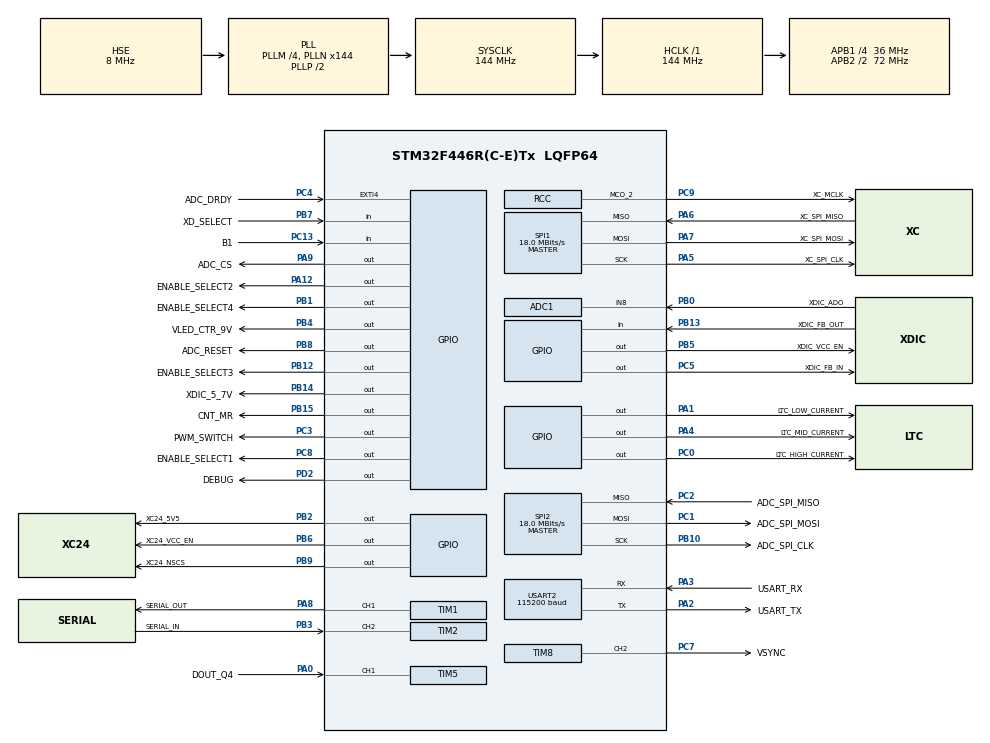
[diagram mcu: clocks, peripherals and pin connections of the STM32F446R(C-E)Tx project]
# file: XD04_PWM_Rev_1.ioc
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ADC1.Channel-0\#ChannelRegularConversion=ADC_CHANNEL_8
ADC1.ContinuousConvMode=DISABLE
ADC1.NbrOfConversionFlag=1
ADC1.Rank-0\#ChannelRegularConversion=1
ADC1.SamplingTime-0\#ChannelRegularConversion=ADC_SAMPLETIME_480CYCLES
ADC1.ScanConvMode=DISABLE
ADC1.master=1
Dma.Request0=TIM1_CH1
Dma.Request1=TIM5_CH1
Dma.Request2=TIM2_CH2/CH4
Dma.TIM1_CH1.0.Direction=DMA_MEMORY_TO_PERIPH
Dma.TIM1_CH1.0.FIFOMode=DMA_FIFOMODE_DISABLE
Dma.TIM1_CH1.0.Instance=DMA2_Stream1
Dma.TIM1_CH1.0.MemDataAlignment=DMA_MDATAALIGN_HALFWORD
Dma.TIM1_CH1.0.MemInc=DMA_MINC_ENABLE
Dma.TIM1_CH1.0.Mode=DMA_NORMAL
Dma.TIM1_CH1.0.PeriphDataAlignment=DMA_PDATAALIGN_HALFWORD
Dma.TIM1_CH1.0.PeriphInc=DMA_PINC_DISABLE
Dma.TIM1_CH1.0.Priority=DMA_PRIORITY_LOW
Dma.TIM2_CH2/CH4.2.Direction=DMA_PERIPH_TO_MEMORY
Dma.TIM2_CH2/CH4.2.FIFOMode=DMA_FIFOMODE_DISABLE
Dma.TIM2_CH2/CH4.2.Instance=DMA1_Stream6
Dma.TIM2_CH2/CH4.2.MemDataAlignment=DMA_MDATAALIGN_HALFWORD
Dma.TIM2_CH2/CH4.2.MemInc=DMA_MINC_ENABLE
Dma.TIM2_CH2/CH4.2.Mode=DMA_NORMAL
Dma.TIM2_CH2/CH4.2.PeriphDataAlignment=DMA_PDATAALIGN_HALFWORD
Dma.TIM2_CH2/CH4.2.PeriphInc=DMA_PINC_DISABLE
Dma.TIM2_CH2/CH4.2.Priority=DMA_PRIORITY_LOW
Dma.TIM5_CH1.1.Direction=DMA_PERIPH_TO_MEMORY
Dma.TIM5_CH1.1.FIFOMode=DMA_FIFOMODE_DISABLE
Dma.TIM5_CH1.1.Instance=DMA1_Stream2
Dma.TIM5_CH1.1.MemDataAlignment=DMA_MDATAALIGN_WORD
Dma.TIM5_CH1.1.MemInc=DMA_MINC_ENABLE
Dma.TIM5_CH1.1.Mode=DMA_NORMAL
Dma.TIM5_CH1.1.PeriphDataAlignment=DMA_PDATAALIGN_WORD
Dma.TIM5_CH1.1.PeriphInc=DMA_PINC_DISABLE
Dma.TIM5_CH1.1.Priority=DMA_PRIORITY_LOW
Mcu.Family=STM32F4
Mcu.Name=STM32F446R(C-E)Tx
Mcu.Package=LQFP64
NVIC.DMA1_Stream2_IRQn=true\:0\:0\:false\:false\:true\:false\:true\:true
NVIC.DMA1_Stream6_IRQn=true\:0\:0\:false\:false\:true\:false\:true\:true
NVIC.DMA2_Stream1_IRQn=true\:0\:0\:false\:false\:true\:false\:true\:true
NVIC.EXTI4_IRQn=true\:0\:0\:false\:false\:true\:true\:true\:true
NVIC.PriorityGroup=NVIC_PRIORITYGROUP_4
NVIC.TIM8_UP_TIM13_IRQn=true\:1\:0\:true\:false\:true\:true\:true\:true
NVIC.USART2_IRQn=true\:5\:0\:true\:false\:true\:true\:true\:true
PA0-WKUP.GPIO_Label=DOUT_Q4
PA0-WKUP.GPIO_PuPd=GPIO_NOPULL
PA0-WKUP.Signal=S_TIM5_CH1
PA1.GPIO_Label=LTC_LOW_CURRENT
PA1.GPIO_Speed=GPIO_SPEED_FREQ_VERY_HIGH
PA1.PinState=GPIO_PIN_SET
PA1.Signal=GPIO_Output
PA12.GPIO_Label=ENABLE_SELECT2
PA12.GPIO_Speed=GPIO_SPEED_FREQ_VERY_HIGH
PA12.PinState=GPIO_PIN_SET
PA12.Signal=GPIO_Output
PA13.GPIO_Label=TMS
PA13.Mode=Serial_Wire
PA13.Signal=SYS_JTMS-SWDIO
PA14.GPIO_Label=TCK
PA14.Mode=Serial_Wire
PA14.Signal=SYS_JTCK-SWCLK
PA2.GPIO_Label=USART_TX
PA2.Mode=Asynchronous
PA2.Signal=USART2_TX
PA3.GPIO_Label=USART_RX
PA3.Mode=Asynchronous
PA3.Signal=USART2_RX
PA4.GPIO_Label=LTC_MID_CURRENT
PA4.GPIO_Speed=GPIO_SPEED_FREQ_VERY_HIGH
PA4.PinState=GPIO_PIN_SET
PA4.Signal=GPIO_Output
PA5.GPIO_Label=XC_SPI_CLK
PA5.Mode=Full_Duplex_Master
PA5.Signal=SPI1_SCK
PA6.GPIO_Label=XC_SPI_MISO
PA6.Mode=Full_Duplex_Master
PA6.Signal=SPI1_MISO
PA7.GPIO_Label=XC_SPI_MOSI
PA7.Mode=Full_Duplex_Master
PA7.Signal=SPI1_MOSI
PA8.GPIO_Label=SERIAL_OUT
PA8.GPIO_PuPd=GPIO_PULLDOWN
PA8.GPIO_Speed=GPIO_SPEED_FREQ_VERY_HIGH
PA8.Signal=S_TIM1_CH1
PA9.GPIO_Label=ADC_CS
PA9.GPIO_Speed=GPIO_SPEED_FREQ_VERY_HIGH
PA9.PinState=GPIO_PIN_SET
PA9.Signal=GPIO_Output
PB0.GPIO_Label=XDIC_ADO
PB0.Signal=ADCx_IN8
PB1.GPIO_Label=ENABLE_SELECT4
PB1.GPIO_Speed=GPIO_SPEED_FREQ_VERY_HIGH
PB1.PinState=GPIO_PIN_SET
PB1.Signal=GPIO_Output
PB10.GPIO_Label=ADC_SPI_CLK
PB10.Mode=Full_Duplex_Master
PB10.Signal=SPI2_SCK
PB12.GPIO_Label=ENABLE_SELECT3
PB12.GPIO_Speed=GPIO_SPEED_FREQ_VERY_HIGH
PB12.PinState=GPIO_PIN_SET
PB12.Signal=GPIO_Output
PB13.GPIO_Label=XDIC_FB_OUT
PB13.Signal=GPIO_Input
PB14.GPIO_Label=XDIC_5_7V
PB14.GPIO_Speed=GPIO_SPEED_FREQ_VERY_HIGH
PB14.Signal=GPIO_Output
PB15.GPIO_Label=CNT_MR
PB15.PinState=GPIO_PIN_SET
PB15.Signal=GPIO_Output
PB2.GPIO_Label=XC24_5V5
PB2.Signal=GPIO_Output
PB3.GPIO_Label=SERIAL_IN
PB3.GPIO_PuPd=GPIO_PULLDOWN
PB3.GPIO_Speed=GPIO_SPEED_FREQ_VERY_HIGH
PB3.Signal=S_TIM2_CH2
PB4.GPIO_Label=VLED_CTR_9V
PB4.GPIO_Speed=GPIO_SPEED_FREQ_VERY_HIGH
PB4.PinState=GPIO_PIN_SET
PB4.Signal=GPIO_Output
PB5.GPIO_Label=XDIC_VCC_EN
PB5.GPIO_Speed=GPIO_SPEED_FREQ_VERY_HIGH
PB5.PinState=GPIO_PIN_SET
PB5.Signal=GPIO_Output
PB6.GPIO_Label=XC24_VCC_EN
PB6.Signal=GPIO_Output
PB7.GPIO_Label=XD_SELECT
PB7.Signal=GPIO_Input
PB8.GPIO_Label=ADC_RESET
PB8.PinState=GPIO_PIN_SET
PB8.Signal=GPIO_Output
PB9.GPIO_Label=XC24_NSCS
PB9.GPIO_Speed=GPIO_SPEED_FREQ_VERY_HIGH
PB9.Signal=GPIO_Output
PC0.GPIO_Label=LTC_HIGH_CURRENT
PC0.GPIO_Speed=GPIO_SPEED_FREQ_VERY_HIGH
PC0.PinState=GPIO_PIN_SET
PC0.Signal=GPIO_Output
PC1.GPIO_Label=ADC_SPI_MOSI
PC1.Mode=Full_Duplex_Master
PC1.Signal=SPI2_MOSI
PC13.GPIO_Label=B1
PC13.GPIO_PuPd=GPIO_PULLUP
PC13.Signal=GPIO_Input
PC14-OSC32_IN.Mode=LSE-External-Oscillator
PC14-OSC32_IN.Signal=RCC_OSC32_IN
PC15-OSC32_OUT.Mode=LSE-External-Oscillator
PC15-OSC32_OUT.Signal=RCC_OSC32_OUT
PC2.GPIO_Label=ADC_SPI_MISO
PC2.Mode=Full_Duplex_Master
PC2.Signal=SPI2_MISO
PC3.GPIO_Label=PWM_SWITCH
PC3.GPIO_Speed=GPIO_SPEED_FREQ_VERY_HIGH
PC3.Signal=GPIO_Output
PC4.GPIO_Label=ADC_DRDY
PC4.GPIO_ModeDefaultEXTI=GPIO_MODE_IT_FALLING
PC4.GPIO_PuPd=GPIO_PULLUP
PC4.Signal=GPXTI4
PC5.GPIO_Label=XDIC_FB_IN
PC5.Signal=GPIO_Output
PC7.GPIO_Label=VSYNC
PC7.Signal=S_TIM8_CH2
PC8.GPIO_Label=ENABLE_SELECT1
PC8.GPIO_Speed=GPIO_SPEED_FREQ_VERY_HIGH
PC8.PinState=GPIO_PIN_SET
PC8.Signal=GPIO_Output
PC9.GPIO_Label=XC_MCLK
PC9.Mode=Clock-out-2
PC9.Signal=RCC_MCO_2
PD2.GPIO_Label=DEBUG
PD2.Signal=GPIO_Output
PH0-OSC_IN.Mode=HSE-External-Oscillator
PH0-OSC_IN.Signal=RCC_OSC_IN
PH1-OSC_OUT.Mode=HSE-External-Oscillator
PH1-OSC_OUT.Signal=RCC_OSC_OUT
ProjectManager.HeapSize=0x200
ProjectManager.StackSize=0x800
ProjectManager.TargetToolchain=EWARM V8.32
RCC.48MHZClocksFreq_Value=84000000
RCC.AHBFreq_Value=144000000
RCC.APB1CLKDivider=RCC_HCLK_DIV4
RCC.APB1Freq_Value=36000000
RCC.APB1TimFreq_Value=72000000
RCC.APB2CLKDivider=RCC_HCLK_DIV2
RCC.APB2Freq_Value=72000000
RCC.APB2TimFreq_Value=144000000
RCC.CortexFreq_Value=144000000
RCC.FLatency-AdvancedSettings=FLASH_LATENCY_4
RCC.HCLKFreq_Value=144000000
RCC.HSE_VALUE=8000000
RCC.HSI_VALUE=16000000
RCC.PLLI2SM=8
RCC.PLLI2SN=400
RCC.PLLI2SR=4
RCC.PLLM=4
RCC.PLLN=144
RCC.PLLSourceVirtual=RCC_PLLSOURCE_HSE
RCC.RCC_MCO1Source=RCC_MCO1SOURCE_PLLCLK
RCC.RCC_MCO2Source=RCC_MCO2SOURCE_PLLI2SCLK
RCC.RCC_MCODiv2=RCC_MCODIV_4
RCC.SYSCLKFreq_VALUE=144000000
RCC.SYSCLKSource=RCC_SYSCLKSOURCE_PLLCLK
RCC.USBFreq_Value=144000000
RCC.VCOOutputFreq_Value=288000000
SH.ADCx_IN8.0=ADC1_IN8,IN8
SH.S_TIM1_CH1.0=TIM1_CH1,PWM Generation1 CH1
SH.S_TIM2_CH2.0=TIM2_CH2,PWM_Input_2
SH.S_TIM5_CH1.0=TIM5_CH1,Input_Capture1_from_TI1
SH.S_TIM8_CH2.0=TIM8_CH2,PWM Generation2 CH2
SPI1.BaudRatePrescaler=SPI_BAUDRATEPRESCALER_4
SPI1.CLKPhase=SPI_PHASE_2EDGE
SPI1.CalculateBaudRate=18.0 MBits/s
SPI1.DataSize=SPI_DATASIZE_16BIT
SPI1.Direction=SPI_DIRECTION_2LINES
SPI1.Mode=SPI_MODE_MASTER
SPI1.VirtualType=VM_MASTER
SPI2.BaudRatePrescaler=SPI_BAUDRATEPRESCALER_2
SPI2.CLKPhase=SPI_PHASE_2EDGE
SPI2.CalculateBaudRate=18.0 MBits/s
SPI2.Direction=SPI_DIRECTION_2LINES
SPI2.Mode=SPI_MODE_MASTER
SPI2.VirtualType=VM_MASTER
TIM1.AutomaticOutput=TIM_AUTOMATICOUTPUT_ENABLE
TIM1.Channel-PWM\ Generation1\ CH1=TIM_CHANNEL_1
TIM1.Period=143
TIM12.AutoReloadPreload=TIM_AUTORELOAD_PRELOAD_ENABLE
TIM12.ClockDivision=TIM_CLOCKDIVISION_DIV1
TIM12.Period=65535
TIM12.Prescaler=71
TIM2.ICPolarity_1=TIM_INPUTCHANNELPOLARITY_FALLING
TIM5.AutoReloadPreload=TIM_AUTORELOAD_PRELOAD_ENABLE
TIM5.Channel-Input_Capture1_from_TI1=TIM_CHANNEL_1
TIM5.Prescaler=0
TIM8.AutomaticOutput=TIM_AUTOMATICOUTPUT_ENABLE
TIM8.Channel-PWM\ Generation2\ CH2=TIM_CHANNEL_2
TIM8.Period=39999
TIM8.Prescaler=29
TIM8.Pulse-PWM\ Generation2\ CH2=40
USART2.BaudRate=115200
USART2.VirtualMode=VM_ASYNC
VP_TIM12_VS_ClockSourceINT.Mode=Internal
VP_TIM1_VS_ClockSourceINT.Mode=Internal
VP_TIM2_VS_ClockSourceINT.Mode=Internal
VP_TIM5_VS_ClockSourceINT.Mode=Internal
VP_TIM8_VS_ClockSourceINT.Mode=Internal
board=NUCLEO-F446RE

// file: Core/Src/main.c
/* USER CODE BEGIN Header */
/**
  ******************************************************************************
  * @file           : main.c
  * @brief          : Main program body
  ******************************************************************************
  * @attention
  *
  * <h2><center>&copy; Copyright (c) 2021 STMicroelectronics.
  * All rights reserved.</center></h2>
  *
  * This software component is licensed by ST under Ultimate Liberty license
  * SLA0044, the "License"; You may not use this file except in compliance with
  * the License. You may obtain a copy of the License at:
  *                             www.st.com/SLA0044
  *
  ******************************************************************************
  */
#define __XDIC_MAIN_C__
#include <stdint.h>
/* USER CODE END Header */
#include "main.h"

/* USER CODE BEGIN Includes */
#include "config.h"
#include "types.h"
#include "jigbd_if.h"
#include "xc24.h"
#include "xd_trim.h"
#include "ads124s08.h"
#include "vsync_task.h"
#include "xdic.h"
#include "xc_trim.h"
/* USER CODE END Includes */

/* USER CODE BEGIN PD */
#define RX_PACKET_SIZE  64
#define RX_BUFF_SIZE    32

typedef void (*func_t)(void);

typedef struct tag_KEY_INFO
{
    uint32_t now_state;
    uint32_t prev_state;
    uint8_t press_cnt;
    uint8_t odd_even;
    func_t function[2];
} key_info_t;
/* USER CODE END PD */

/* USER CODE BEGIN PV */
void key_func_1(void)
{
    XDIC_Sweep_LDO();
}

void key_func_2(void)
{
    // Off LED
    NVIC_SystemReset();
}

static key_info_t gt_key_info = {
    .now_state = 1,
    .prev_state = 1,
    .press_cnt = 0,
    .odd_even = 0,
    .function = { key_func_1, key_func_2 },
};

static uint8_t gn_key_task_tick;

void btn_process(void)
{
    if (gn_key_task_tick == 0)
    {
        gt_key_info.now_state = LL_GPIO_IsInputPinSet(B1_GPIO_Port, B1_Pin);
        if (gt_key_info.now_state != gt_key_info.prev_state)
        {
            if (gt_key_info.now_state == 0)
            {
            }
            else
            {
                // Button Released
                if (gt_key_info.press_cnt >= 30)
                {
                    if (gt_key_info.function[gt_key_info.odd_even] != NULL)
                    {
                        gt_key_info.function[gt_key_info.odd_even]();
                    }
                    gt_key_info.odd_even ^= 1;
                }
                gt_key_info.press_cnt = 0;
            }
            gt_key_info.prev_state = gt_key_info.now_state;
        }
        else
        {
            if (gt_key_info.now_state == 0)
            {
                // Button Pressed
                ++gt_key_info.press_cnt;
            }
            else
            {
                // nothing
            }
        }
        gn_key_task_tick = 10; //10ms
    }
}

typedef struct
{
    uint16_t length;
    char buffer[RX_PACKET_SIZE];
} rx_packet_t;

typedef struct
{
    uint16_t RxInCnt;
    uint16_t RxOutCnt;
    rx_packet_t Rxbuff[RX_BUFF_SIZE];
} RX_UART_t;
static RX_UART_t gt_rx_uart;

static bool gb_xd_run_trim_task;
static bool gb_xd_run_screen_task;

static bool gb_xc_run_trim_task;

static LOG_LV_T gt_log_lv = LOG_INFO;
/* USER CODE END PV */

void SystemClock_Config(void);
void PeriphCommonClock_Config(void);
static void MX_GPIO_Init(void);
static void MX_DMA_Init(void);
static void MX_USART2_UART_Init(void);
static void MX_TIM12_Init(void);
static void MX_SPI2_Init(void);
static void MX_TIM5_Init(void);
static void MX_SPI1_Init(void);
static void MX_ADC1_Init(void);
static void MX_TIM8_Init(void);
static void MX_TIM1_Init(void);
static void MX_TIM2_Init(void);
/* USER CODE BEGIN PFP */
static void JigTestMainTask(void);
static void TaskDebugUart(void);
/* USER CODE END PFP */

/* USER CODE BEGIN 0 */
void sys_tick_handler(void)
{
    if (gb_xd_run_trim_task == false)
    {
        gb_xd_run_trim_task = true;
    }
    if (gb_xd_run_screen_task == false)
    {
        gb_xd_run_screen_task = true;
    }
    if (gb_xc_run_trim_task == false)
    {
        gb_xc_run_trim_task = true;
    }
    if (gn_xd_rx_timeout)
    {
        --gn_xd_rx_timeout;
    }
    if (gn_xc_spi_timeout)
    {
        --gn_xc_spi_timeout;
    }
    if (gn_key_task_tick)
    {
        --gn_key_task_tick;
    }
    if (gn_ads114s08_read_timeout)
    {
        --gn_ads114s08_read_timeout;
    }
}

void print(LOG_LV_T log_lv, const char *fmt, ...)
{
    if (log_lv >= gt_log_lv)
    {
        int len = 0;
        char msg_buffer[PRINT_BUFF_SIZE] = {0, };

        if (log_lv > LOG_INFO)
        {
            char temp_buffer[PRINT_BUFF_SIZE] = {0, };
            snprintf(temp_buffer, PRINT_BUFF_SIZE - 1, "%s%s%s", ANSI_FONT_RED, fmt, ANSI_FONT_NONE);
            fmt = temp_buffer;
        }

        va_list ap;
        va_start(ap, fmt);
        len = vsnprintf(msg_buffer, (PRINT_BUFF_SIZE - 1), fmt, ap);
        va_end(ap);

        for (int i = 0 ; i < len ; ++i)
        {
            /* Loop until the end of transmission */
            while (RESET == LL_USART_IsActiveFlag_TXE(USART2));
            /* Echo received character on TX */
            LL_USART_TransmitData8(USART2, (uint8_t)msg_buffer[i]);
        }
    }
}

void comm_print_help(void)
{
    print(LOG_INFO, "\n\r------------------ Command Help -----------------------------");

    print(LOG_INFO, "\n\r  help / ?\t\t : Show command help");
    print(LOG_INFO, "\n\r  jig_ic_start\t\t : Start timer for frequency input capture");
    print(LOG_INFO, "\n\r  jig_ic_stop\t\t : Stop input capture and print measured frequency");
    print(LOG_INFO, "\n\r  jig_vref_start\t : Start MCU ADC");

    print(LOG_INFO, "\n\r  jig_ch_sel [d]\t : Select output channel (0 ~ XD_CH_MAX)");
    print(LOG_INFO, "\n\r  jig_xd_vcc [u]\t : XD VCC On/Off (1=On, 0=Off)");
    print(LOG_INFO, "\n\r  jig_xd_vcc_level [u]\t : XD VCC level (0=5V, 1=5.7V)");
    print(LOG_INFO, "\n\r  jig_xc_vcc [u]\t : XC VCC On/Off (1=On, 0=Off)");
    print(LOG_INFO, "\n\r  jig_vled [u]\t\t : VLED 9V On/Off (1=On, 0=Off)");
    print(LOG_INFO, "\n\r  jig_gain [u]\t\t : Set current gain (0 ~ GAIN_MAX-1)");
    print(LOG_INFO, "\n\r  jig_vsync [d]\t\t : Start/Stop Vsync (1=Start, 0=Stop)");
    print(LOG_INFO, "\n\r  vsync [lf]\t\t : Set vsync frequency (Hz)");
    print(LOG_INFO, "\n\r  pwm_freq [lf]\t\t : Set PWM frequency (kHz)");

    print(LOG_INFO, "\n\r  xd_idgen\t\t : Send IDGEN command to XDIC");
    print(LOG_INFO, "\n\r  xd_reset\t\t : Reset XDIC");
    print(LOG_INFO, "\n\r  xd_syncgen\t\t : Send SYNCGEN command to XDIC");
    print(LOG_INFO, "\n\r  xd_test_en\t\t : Enter trim mode of XDIC");
    print(LOG_INFO, "\n\r  xd_r_all\t\t : Read all registers of XDIC");
    print(LOG_INFO, "\n\r  xd_r [x]\t\t : Read general register [x] (HEX)");
    print(LOG_INFO, "\n\r  xd_rt [x]\t\t : Read trim register [x] (HEX)");
    print(LOG_INFO, "\n\r  xd_w [x] [y]\t\t : Write [y] to general register [x] (HEX)");
    print(LOG_INFO, "\n\r  xd_wt [x] [y]\t\t : Write [y] to trim register [x] (HEX)");
    print(LOG_INFO, "\n\r  xd_ldim [d]\t\t : Set LDIM value [0 ~ 65535]");
    print(LOG_INFO, "\n\r  xd_ldim\t\t : Show current LDIM value");
    print(LOG_INFO, "\n\r  xd_fbi [x]\t\t : Set FBI pin (1=HI, 0=LO)");
    print(LOG_INFO, "\n\r  xd_fbo\t\t : Read FBO pin status");
    print(LOG_INFO, "\n\r  xd_ch [d]\t\t : Set XDIC channel (0 ~ XD_CH_MAX)");

    print(LOG_INFO, "\n\r  xd_debug\t\t : Initialize XD debug environment");
    print(LOG_INFO, "\n\r  xd_trim_debug\t : Initialize XD trim environment");
    print(LOG_INFO, "\n\r  xd_trim_vref\t\t : Trim VREF of XDIC");
    print(LOG_INFO, "\n\r  xd_trim_osc\t\t : Trim OSC of XDIC");
    print(LOG_INFO, "\n\r  xd_trim_ofs [x]\t : Trim offset and fix LD to 1<<12");
    print(LOG_INFO, "\n\r  xd_trim_gain [x]\t : Trim gain and fix LD to 6<<12");
    print(LOG_INFO, "\n\r  xd_osc_debug\t\t : Auto scan OSC trim values");

    print(LOG_INFO, "\n\r  xc_debug\t\t : Initialize XC24");
    print(LOG_INFO, "\n\r  xc_r [x]\t\t : Read register [x] of XC24 (HEX)");
    print(LOG_INFO, "\n\r  xc_w [x] [y]\t\t : Write [y] to register [x] of XC24 (HEX)");
    print(LOG_INFO, "\n\r  xc_r_all\t\t : Read all registers of XC24");
    print(LOG_INFO, "\n\r  xc_use [d]\t\t : Enable/Disable XC24 usage (0/1)");

    print(LOG_INFO, "\n\r  xd_trim_start / 1\t : Start XDIC trim process");
    print(LOG_INFO, "\n\r  xd_screen_start / 2\t : Start XDIC screen process");
    print(LOG_INFO, "\n\r  xd_dimming_start / 3\t : Start XDIC dimming process");
    print(LOG_INFO, "\n\r  xc_trim_start / 4\t : Start XC24 trim process");

    print(LOG_INFO, "\n\r  log_lv [d]\t\t : Set log level (0 ~ LOG_MAX-1)");
    print(LOG_INFO, "\n\r  reset\t\t\t : Reset MCU");

    print(LOG_INFO, "\n\r--------------------------------------------------------------\n\r");
}

void comm_init(void)
{
    print(LOG_INFO, "\n\r--------------------------------------");
    print(LOG_INFO, "\n\r    [GT-XD04 PWM (ES2) JIG]");
    print(LOG_INFO, "\n\r--------------------------------------");
    print(LOG_INFO, "\n\r - Author: xxx@glbltech.com");
    print(LOG_INFO, "\n\r - Build : %s", __DATE__);
    print(LOG_INFO, "\r\n -%s %s %s", ANSI_FONT_YELLOW, (IS_XC24_Support() ? "XC24 ES2 REV ES2 IS SELECTED!" : "NOT SUPPORT XC24"), ANSI_FONT_NONE);
    print(LOG_INFO, "\r\n -%s %s %s", ANSI_FONT_YELLOW, (XD_Trim_IF_Get_OTP_Enable() ? "XDIC OTP WRITE ENABLE" : "XDIC OTP WRITE DISABLE"), ANSI_FONT_NONE);
    print(LOG_INFO, "\r\n -%s %s %s", ANSI_FONT_YELLOW, (XC_Trim_IF_Get_OTP_Enable() ? "XC24 OTP WRITE ENABLE" : "XC24 OTP WRITE DISABLE"), ANSI_FONT_NONE);
    print(LOG_INFO, "\n\r--------------------------------------\r\n");
}
/* USER CODE END 0 */

int main(void)
{

  /* MCU Configuration--------------------------------------------------------*/

  /* Reset of all peripherals, Initializes the Flash interface and the Systick. */
  HAL_Init();

  /* Configure the system clock */
  SystemClock_Config();

  /* Configure the peripherals common clocks */
  PeriphCommonClock_Config();

  /* Initialize all configured peripherals */
  MX_GPIO_Init();
  MX_DMA_Init();
  MX_USART2_UART_Init();
  MX_TIM12_Init();
  MX_SPI2_Init();
  MX_TIM5_Init();
  MX_SPI1_Init();
  MX_ADC1_Init();
  MX_TIM8_Init();
  MX_TIM1_Init();
  MX_TIM2_Init();
  /* USER CODE BEGIN 2 */

    USE_XC24(FALSE);
    XD_Trim_IF_Set_OTP_Enable(FALSE);
    XC_Trim_IF_Set_OTP_Enable(FALSE);
    XC24_Start_MCLK_Oscillation(FALSE);
    JigBD_IF_Link_DMA_With_Buffer();

    XD_Trim_Calculate_Spec();
    ADS114S08_Init();

    LL_TIM_EnableCounter(TIM1); /* PWM Output for ... */
    LL_TIM_EnableCounter(TIM2); /* PWM Input for ... */
    LL_TIM_EnableCounter(TIM5); /* for Freq Input */

    /* DMA2_Stream2_IRQn interrupt configuration */
    NVIC_SetPriority(DMA2_Stream2_IRQn, NVIC_EncodePriority(NVIC_GetPriorityGrouping(),0, 0));
    NVIC_EnableIRQ(DMA2_Stream2_IRQn);

    comm_init();

  /* USER CODE END 2 */

  /* Infinite loop */
  while (1)
  {

    /* USER CODE BEGIN 3 */
    JigTestMainTask();
    TaskDebugUart();
    XDIC_Vsync_Task();
    btn_process();
  }
  /* USER CODE END 3 */
}

void SystemClock_Config(void)
{
  RCC_OscInitTypeDef RCC_OscInitStruct = {0};
  RCC_ClkInitTypeDef RCC_ClkInitStruct = {0};

  /** Configure the main internal regulator output voltage
  */
  __HAL_RCC_PWR_CLK_ENABLE();
  __HAL_PWR_VOLTAGESCALING_CONFIG(PWR_REGULATOR_VOLTAGE_SCALE1);

  /** Initializes the RCC Oscillators according to the specified parameters
  * in the RCC_OscInitTypeDef structure.
  */
  RCC_OscInitStruct.OscillatorType = RCC_OSCILLATORTYPE_HSE;
  RCC_OscInitStruct.HSEState = RCC_HSE_ON;
  RCC_OscInitStruct.HSIState = RCC_HSI_ON;
  RCC_OscInitStruct.HSICalibrationValue = RCC_HSICALIBRATION_DEFAULT;
  RCC_OscInitStruct.PLL.PLLState = RCC_PLL_ON;
  RCC_OscInitStruct.PLL.PLLSource = RCC_PLLSOURCE_HSE;
  RCC_OscInitStruct.PLL.PLLM = 4;
  RCC_OscInitStruct.PLL.PLLN = 144;
  RCC_OscInitStruct.PLL.PLLP = RCC_PLLP_DIV2;
  RCC_OscInitStruct.PLL.PLLQ = 2;
  RCC_OscInitStruct.PLL.PLLR = 2;
  if (HAL_RCC_OscConfig(&RCC_OscInitStruct) != HAL_OK)
  {
    Error_Handler();
  }

  /** Initializes the CPU, AHB and APB buses clocks
  */
  RCC_ClkInitStruct.ClockType = RCC_CLOCKTYPE_HCLK|RCC_CLOCKTYPE_SYSCLK
                              |RCC_CLOCKTYPE_PCLK1|RCC_CLOCKTYPE_PCLK2;
  RCC_ClkInitStruct.SYSCLKSource = RCC_SYSCLKSOURCE_PLLCLK;
  RCC_ClkInitStruct.AHBCLKDivider = RCC_SYSCLK_DIV1;
  RCC_ClkInitStruct.APB1CLKDivider = RCC_HCLK_DIV4;
  RCC_ClkInitStruct.APB2CLKDivider = RCC_HCLK_DIV2;

  if (HAL_RCC_ClockConfig(&RCC_ClkInitStruct, FLASH_LATENCY_4) != HAL_OK)
  {
    Error_Handler();
  }
  HAL_RCC_MCOConfig(RCC_MCO2, RCC_MCO2SOURCE_PLLI2SCLK, RCC_MCODIV_4);
}

void PeriphCommonClock_Config(void)
{
  RCC_PeriphCLKInitTypeDef PeriphClkInitStruct = {0};

  /** Initializes the peripherals clock
  */
  PeriphClkInitStruct.PeriphClockSelection = RCC_PERIPHCLK_PLLI2S;
  PeriphClkInitStruct.PLLI2S.PLLI2SN = 400;
  PeriphClkInitStruct.PLLI2S.PLLI2SP = RCC_PLLI2SP_DIV2;
  PeriphClkInitStruct.PLLI2S.PLLI2SM = 8;
  PeriphClkInitStruct.PLLI2S.PLLI2SR = 4;
  PeriphClkInitStruct.PLLI2S.PLLI2SQ = 2;
  PeriphClkInitStruct.PLLI2SDivQ = 1;
  if (HAL_RCCEx_PeriphCLKConfig(&PeriphClkInitStruct) != HAL_OK)
  {
    Error_Handler();
  }
}

static void MX_ADC1_Init(void)
{

  LL_ADC_InitTypeDef ADC_InitStruct = {0};
  LL_ADC_REG_InitTypeDef ADC_REG_InitStruct = {0};
  LL_ADC_CommonInitTypeDef ADC_CommonInitStruct = {0};

  LL_GPIO_InitTypeDef GPIO_InitStruct = {0};

  /* Peripheral clock enable */
  LL_APB2_GRP1_EnableClock(LL_APB2_GRP1_PERIPH_ADC1);

  LL_AHB1_GRP1_EnableClock(LL_AHB1_GRP1_PERIPH_GPIOB);
  /**ADC1 GPIO Configuration
  PB0   ------> ADC1_IN8
  */
  GPIO_InitStruct.Pin = XDIC_ADO_Pin;
  GPIO_InitStruct.Mode = LL_GPIO_MODE_ANALOG;
  GPIO_InitStruct.Pull = LL_GPIO_PULL_NO;
  LL_GPIO_Init(XDIC_ADO_GPIO_Port, &GPIO_InitStruct);

  /** Common config
  */
  ADC_InitStruct.Resolution = LL_ADC_RESOLUTION_12B;
  ADC_InitStruct.DataAlignment = LL_ADC_DATA_ALIGN_RIGHT;
  ADC_InitStruct.SequencersScanMode = LL_ADC_SEQ_SCAN_DISABLE;
  LL_ADC_Init(ADC1, &ADC_InitStruct);
  ADC_REG_InitStruct.TriggerSource = LL_ADC_REG_TRIG_SOFTWARE;
  ADC_REG_InitStruct.SequencerLength = LL_ADC_REG_SEQ_SCAN_DISABLE;
  ADC_REG_InitStruct.SequencerDiscont = LL_ADC_REG_SEQ_DISCONT_DISABLE;
  ADC_REG_InitStruct.ContinuousMode = LL_ADC_REG_CONV_SINGLE;
  ADC_REG_InitStruct.DMATransfer = LL_ADC_REG_DMA_TRANSFER_NONE;
  LL_ADC_REG_Init(ADC1, &ADC_REG_InitStruct);
  LL_ADC_REG_SetFlagEndOfConversion(ADC1, LL_ADC_REG_FLAG_EOC_UNITARY_CONV);
  ADC_CommonInitStruct.CommonClock = LL_ADC_CLOCK_SYNC_PCLK_DIV2;
  ADC_CommonInitStruct.Multimode = LL_ADC_MULTI_INDEPENDENT;
  LL_ADC_CommonInit(__LL_ADC_COMMON_INSTANCE(ADC1), &ADC_CommonInitStruct);

  /** Configure Regular Channel
  */
  LL_ADC_REG_SetSequencerRanks(ADC1, LL_ADC_REG_RANK_1, LL_ADC_CHANNEL_8);
  LL_ADC_SetChannelSamplingTime(ADC1, LL_ADC_CHANNEL_8, LL_ADC_SAMPLINGTIME_480CYCLES);
  /* USER CODE BEGIN ADC1_Init 2 */
    LL_ADC_Enable(ADC1);
  /* USER CODE END ADC1_Init 2 */

}

static void MX_SPI1_Init(void)
{

  LL_SPI_InitTypeDef SPI_InitStruct = {0};

  LL_GPIO_InitTypeDef GPIO_InitStruct = {0};

  /* Peripheral clock enable */
  LL_APB2_GRP1_EnableClock(LL_APB2_GRP1_PERIPH_SPI1);

  LL_AHB1_GRP1_EnableClock(LL_AHB1_GRP1_PERIPH_GPIOA);
  /**SPI1 GPIO Configuration
  PA5   ------> SPI1_SCK
  PA6   ------> SPI1_MISO
  PA7   ------> SPI1_MOSI
  */
  GPIO_InitStruct.Pin = XC_SPI_CLK_Pin|XC_SPI_MISO_Pin|XC_SPI_MOSI_Pin;
  GPIO_InitStruct.Mode = LL_GPIO_MODE_ALTERNATE;
  GPIO_InitStruct.Speed = LL_GPIO_SPEED_FREQ_VERY_HIGH;
  GPIO_InitStruct.OutputType = LL_GPIO_OUTPUT_PUSHPULL;
  GPIO_InitStruct.Pull = LL_GPIO_PULL_NO;
  GPIO_InitStruct.Alternate = LL_GPIO_AF_5;
  LL_GPIO_Init(GPIOA, &GPIO_InitStruct);

  /* SPI1 parameter configuration*/
  SPI_InitStruct.TransferDirection = LL_SPI_FULL_DUPLEX;
  SPI_InitStruct.Mode = LL_SPI_MODE_MASTER;
  SPI_InitStruct.DataWidth = LL_SPI_DATAWIDTH_16BIT;
  SPI_InitStruct.ClockPolarity = LL_SPI_POLARITY_LOW;
  SPI_InitStruct.ClockPhase = LL_SPI_PHASE_2EDGE;
  SPI_InitStruct.NSS = LL_SPI_NSS_SOFT;
  SPI_InitStruct.BaudRate = LL_SPI_BAUDRATEPRESCALER_DIV4;
  SPI_InitStruct.BitOrder = LL_SPI_MSB_FIRST;
  SPI_InitStruct.CRCCalculation = LL_SPI_CRCCALCULATION_DISABLE;
  SPI_InitStruct.CRCPoly = 10;
  LL_SPI_Init(SPI1, &SPI_InitStruct);
  LL_SPI_SetStandard(SPI1, LL_SPI_PROTOCOL_MOTOROLA);
  /* USER CODE BEGIN SPI1_Init 2 */

    //LL_SPI_Enable(SPI1);

  /* USER CODE END SPI1_Init 2 */

}

static void MX_SPI2_Init(void)
{

  LL_SPI_InitTypeDef SPI_InitStruct = {0};

  LL_GPIO_InitTypeDef GPIO_InitStruct = {0};

  /* Peripheral clock enable */
  LL_APB1_GRP1_EnableClock(LL_APB1_GRP1_PERIPH_SPI2);

  LL_AHB1_GRP1_EnableClock(LL_AHB1_GRP1_PERIPH_GPIOC);
  LL_AHB1_GRP1_EnableClock(LL_AHB1_GRP1_PERIPH_GPIOB);
  /**SPI2 GPIO Configuration
  PC1   ------> SPI2_MOSI
  PC2   ------> SPI2_MISO
  PB10   ------> SPI2_SCK
  */
  GPIO_InitStruct.Pin = ADC_SPI_MOSI_Pin;
  GPIO_InitStruct.Mode = LL_GPIO_MODE_ALTERNATE;
  GPIO_InitStruct.Speed = LL_GPIO_SPEED_FREQ_VERY_HIGH;
  GPIO_InitStruct.OutputType = LL_GPIO_OUTPUT_PUSHPULL;
  GPIO_InitStruct.Pull = LL_GPIO_PULL_NO;
  GPIO_InitStruct.Alternate = LL_GPIO_AF_7;
  LL_GPIO_Init(ADC_SPI_MOSI_GPIO_Port, &GPIO_InitStruct);

  GPIO_InitStruct.Pin = ADC_SPI_MISO_Pin;
  GPIO_InitStruct.Mode = LL_GPIO_MODE_ALTERNATE;
  GPIO_InitStruct.Speed = LL_GPIO_SPEED_FREQ_VERY_HIGH;
  GPIO_InitStruct.OutputType = LL_GPIO_OUTPUT_PUSHPULL;
  GPIO_InitStruct.Pull = LL_GPIO_PULL_NO;
  GPIO_InitStruct.Alternate = LL_GPIO_AF_5;
  LL_GPIO_Init(ADC_SPI_MISO_GPIO_Port, &GPIO_InitStruct);

  GPIO_InitStruct.Pin = ADC_SPI_CLK_Pin;
  GPIO_InitStruct.Mode = LL_GPIO_MODE_ALTERNATE;
  GPIO_InitStruct.Speed = LL_GPIO_SPEED_FREQ_VERY_HIGH;
  GPIO_InitStruct.OutputType = LL_GPIO_OUTPUT_PUSHPULL;
  GPIO_InitStruct.Pull = LL_GPIO_PULL_NO;
  GPIO_InitStruct.Alternate = LL_GPIO_AF_5;
  LL_GPIO_Init(ADC_SPI_CLK_GPIO_Port, &GPIO_InitStruct);

  /* SPI2 parameter configuration*/
  SPI_InitStruct.TransferDirection = LL_SPI_FULL_DUPLEX;
  SPI_InitStruct.Mode = LL_SPI_MODE_MASTER;
  SPI_InitStruct.DataWidth = LL_SPI_DATAWIDTH_8BIT;
  SPI_InitStruct.ClockPolarity = LL_SPI_POLARITY_LOW;
  SPI_InitStruct.ClockPhase = LL_SPI_PHASE_2EDGE;
  SPI_InitStruct.NSS = LL_SPI_NSS_SOFT;
  SPI_InitStruct.BaudRate = LL_SPI_BAUDRATEPRESCALER_DIV2;
  SPI_InitStruct.BitOrder = LL_SPI_MSB_FIRST;
  SPI_InitStruct.CRCCalculation = LL_SPI_CRCCALCULATION_DISABLE;
  SPI_InitStruct.CRCPoly = 10;
  LL_SPI_Init(SPI2, &SPI_InitStruct);
  LL_SPI_SetStandard(SPI2, LL_SPI_PROTOCOL_MOTOROLA);

}

static void MX_TIM1_Init(void)
{

  LL_TIM_InitTypeDef TIM_InitStruct = {0};
  LL_TIM_OC_InitTypeDef TIM_OC_InitStruct = {0};
  LL_TIM_BDTR_InitTypeDef TIM_BDTRInitStruct = {0};

  LL_GPIO_InitTypeDef GPIO_InitStruct = {0};

  /* Peripheral clock enable */
  LL_APB2_GRP1_EnableClock(LL_APB2_GRP1_PERIPH_TIM1);

  /* TIM1 DMA Init */

  /* TIM1_CH1 Init */
  LL_DMA_SetChannelSelection(DMA2, LL_DMA_STREAM_1, LL_DMA_CHANNEL_6);

  LL_DMA_SetDataTransferDirection(DMA2, LL_DMA_STREAM_1, LL_DMA_DIRECTION_MEMORY_TO_PERIPH);

  LL_DMA_SetStreamPriorityLevel(DMA2, LL_DMA_STREAM_1, LL_DMA_PRIORITY_LOW);

  LL_DMA_SetMode(DMA2, LL_DMA_STREAM_1, LL_DMA_MODE_NORMAL);

  LL_DMA_SetPeriphIncMode(DMA2, LL_DMA_STREAM_1, LL_DMA_PERIPH_NOINCREMENT);

  LL_DMA_SetMemoryIncMode(DMA2, LL_DMA_STREAM_1, LL_DMA_MEMORY_INCREMENT);

  LL_DMA_SetPeriphSize(DMA2, LL_DMA_STREAM_1, LL_DMA_PDATAALIGN_HALFWORD);

  LL_DMA_SetMemorySize(DMA2, LL_DMA_STREAM_1, LL_DMA_MDATAALIGN_HALFWORD);

  LL_DMA_DisableFifoMode(DMA2, LL_DMA_STREAM_1);

  TIM_InitStruct.Prescaler = 0;
  TIM_InitStruct.CounterMode = LL_TIM_COUNTERMODE_UP;
  TIM_InitStruct.Autoreload = 143;
  TIM_InitStruct.ClockDivision = LL_TIM_CLOCKDIVISION_DIV1;
  TIM_InitStruct.RepetitionCounter = 0;
  LL_TIM_Init(TIM1, &TIM_InitStruct);
  LL_TIM_DisableARRPreload(TIM1);
  LL_TIM_SetClockSource(TIM1, LL_TIM_CLOCKSOURCE_INTERNAL);
  LL_TIM_OC_EnablePreload(TIM1, LL_TIM_CHANNEL_CH1);
  TIM_OC_InitStruct.OCMode = LL_TIM_OCMODE_PWM1;
  TIM_OC_InitStruct.OCState = LL_TIM_OCSTATE_DISABLE;
  TIM_OC_InitStruct.OCNState = LL_TIM_OCSTATE_DISABLE;
  TIM_OC_InitStruct.CompareValue = 0;
  TIM_OC_InitStruct.OCPolarity = LL_TIM_OCPOLARITY_HIGH;
  TIM_OC_InitStruct.OCNPolarity = LL_TIM_OCPOLARITY_HIGH;
  TIM_OC_InitStruct.OCIdleState = LL_TIM_OCIDLESTATE_LOW;
  TIM_OC_InitStruct.OCNIdleState = LL_TIM_OCIDLESTATE_LOW;
  LL_TIM_OC_Init(TIM1, LL_TIM_CHANNEL_CH1, &TIM_OC_InitStruct);
  LL_TIM_OC_DisableFast(TIM1, LL_TIM_CHANNEL_CH1);
  LL_TIM_SetTriggerOutput(TIM1, LL_TIM_TRGO_RESET);
  LL_TIM_DisableMasterSlaveMode(TIM1);
  TIM_BDTRInitStruct.OSSRState = LL_TIM_OSSR_DISABLE;
  TIM_BDTRInitStruct.OSSIState = LL_TIM_OSSI_DISABLE;
  TIM_BDTRInitStruct.LockLevel = LL_TIM_LOCKLEVEL_OFF;
  TIM_BDTRInitStruct.DeadTime = 0;
  TIM_BDTRInitStruct.BreakState = LL_TIM_BREAK_DISABLE;
  TIM_BDTRInitStruct.BreakPolarity = LL_TIM_BREAK_POLARITY_HIGH;
  TIM_BDTRInitStruct.AutomaticOutput = LL_TIM_AUTOMATICOUTPUT_ENABLE;
  LL_TIM_BDTR_Init(TIM1, &TIM_BDTRInitStruct);
  /* USER CODE BEGIN TIM1_Init 2 */

    LL_TIM_CC_EnableChannel(TIM1, LL_TIM_CHANNEL_CH1);
    LL_TIM_EnableDMAReq_CC1(TIM1);

    LL_DMA_ClearFlag_FE1(DMA2);
    LL_DMA_ClearFlag_HT1(DMA2);
    LL_DMA_ClearFlag_TC1(DMA2);

  /* USER CODE END TIM1_Init 2 */
  LL_AHB1_GRP1_EnableClock(LL_AHB1_GRP1_PERIPH_GPIOA);
  /**TIM1 GPIO Configuration
  PA8   ------> TIM1_CH1
  */
  GPIO_InitStruct.Pin = SERIAL_OUT_Pin;
  GPIO_InitStruct.Mode = LL_GPIO_MODE_ALTERNATE;
  GPIO_InitStruct.Speed = LL_GPIO_SPEED_FREQ_VERY_HIGH;
  GPIO_InitStruct.OutputType = LL_GPIO_OUTPUT_PUSHPULL;
  GPIO_InitStruct.Pull = LL_GPIO_PULL_DOWN;
  GPIO_InitStruct.Alternate = LL_GPIO_AF_1;
  LL_GPIO_Init(SERIAL_OUT_GPIO_Port, &GPIO_InitStruct);

}

static void MX_TIM2_Init(void)
{

  LL_TIM_InitTypeDef TIM_InitStruct = {0};

  LL_GPIO_InitTypeDef GPIO_InitStruct = {0};

  /* Peripheral clock enable */
  LL_APB1_GRP1_EnableClock(LL_APB1_GRP1_PERIPH_TIM2);

  LL_AHB1_GRP1_EnableClock(LL_AHB1_GRP1_PERIPH_GPIOB);
  /**TIM2 GPIO Configuration
  PB3   ------> TIM2_CH2
  */
  GPIO_InitStruct.Pin = SERIAL_IN_Pin;
  GPIO_InitStruct.Mode = LL_GPIO_MODE_ALTERNATE;
  GPIO_InitStruct.Speed = LL_GPIO_SPEED_FREQ_VERY_HIGH;
  GPIO_InitStruct.OutputType = LL_GPIO_OUTPUT_PUSHPULL;
  GPIO_InitStruct.Pull = LL_GPIO_PULL_DOWN;
  GPIO_InitStruct.Alternate = LL_GPIO_AF_1;
  LL_GPIO_Init(SERIAL_IN_GPIO_Port, &GPIO_InitStruct);

  /* TIM2 DMA Init */

  /* TIM2_CH2_CH4 Init */
  LL_DMA_SetChannelSelection(DMA1, LL_DMA_STREAM_6, LL_DMA_CHANNEL_3);

  LL_DMA_SetDataTransferDirection(DMA1, LL_DMA_STREAM_6, LL_DMA_DIRECTION_PERIPH_TO_MEMORY);

  LL_DMA_SetStreamPriorityLevel(DMA1, LL_DMA_STREAM_6, LL_DMA_PRIORITY_LOW);

  LL_DMA_SetMode(DMA1, LL_DMA_STREAM_6, LL_DMA_MODE_NORMAL);

  LL_DMA_SetPeriphIncMode(DMA1, LL_DMA_STREAM_6, LL_DMA_PERIPH_NOINCREMENT);

  LL_DMA_SetMemoryIncMode(DMA1, LL_DMA_STREAM_6, LL_DMA_MEMORY_INCREMENT);

  LL_DMA_SetPeriphSize(DMA1, LL_DMA_STREAM_6, LL_DMA_PDATAALIGN_HALFWORD);

  LL_DMA_SetMemorySize(DMA1, LL_DMA_STREAM_6, LL_DMA_MDATAALIGN_HALFWORD);

  LL_DMA_DisableFifoMode(DMA1, LL_DMA_STREAM_6);

  /* USER CODE BEGIN TIM2_Init 1 */

    LL_DMA_SetChannelSelection(DMA1, LL_DMA_STREAM_5, LL_DMA_CHANNEL_3);
    LL_DMA_SetDataTransferDirection(DMA1, LL_DMA_STREAM_5, LL_DMA_DIRECTION_PERIPH_TO_MEMORY);
    LL_DMA_SetStreamPriorityLevel(DMA1, LL_DMA_STREAM_5, LL_DMA_PRIORITY_LOW);
    LL_DMA_SetMode(DMA1, LL_DMA_STREAM_5, LL_DMA_MODE_NORMAL);
    LL_DMA_SetPeriphIncMode(DMA1, LL_DMA_STREAM_5, LL_DMA_PERIPH_NOINCREMENT);
    LL_DMA_SetMemoryIncMode(DMA1, LL_DMA_STREAM_5, LL_DMA_MEMORY_INCREMENT);
    LL_DMA_SetPeriphSize(DMA1, LL_DMA_STREAM_5, LL_DMA_PDATAALIGN_HALFWORD);
    LL_DMA_SetMemorySize(DMA1, LL_DMA_STREAM_5, LL_DMA_MDATAALIGN_HALFWORD);
    LL_DMA_DisableFifoMode(DMA1, LL_DMA_STREAM_5);

  /* USER CODE END TIM2_Init 1 */
  TIM_InitStruct.Prescaler = 0;
  TIM_InitStruct.CounterMode = LL_TIM_COUNTERMODE_UP;
  TIM_InitStruct.Autoreload = 4294967295;
  TIM_InitStruct.ClockDivision = LL_TIM_CLOCKDIVISION_DIV1;
  LL_TIM_Init(TIM2, &TIM_InitStruct);
  LL_TIM_DisableARRPreload(TIM2);
  LL_TIM_SetClockSource(TIM2, LL_TIM_CLOCKSOURCE_INTERNAL);
  LL_TIM_SetTriggerInput(TIM2, LL_TIM_TS_TI2FP2);
  LL_TIM_SetSlaveMode(TIM2, LL_TIM_SLAVEMODE_RESET);
  LL_TIM_CC_DisableChannel(TIM2, LL_TIM_CHANNEL_CH2);
  LL_TIM_IC_SetFilter(TIM2, LL_TIM_CHANNEL_CH2, LL_TIM_IC_FILTER_FDIV1);
  LL_TIM_IC_SetPolarity(TIM2, LL_TIM_CHANNEL_CH2, LL_TIM_IC_POLARITY_RISING);
  LL_TIM_DisableIT_TRIG(TIM2);
  LL_TIM_DisableDMAReq_TRIG(TIM2);
  LL_TIM_IC_SetActiveInput(TIM2, LL_TIM_CHANNEL_CH1, LL_TIM_ACTIVEINPUT_INDIRECTTI);
  LL_TIM_IC_SetPrescaler(TIM2, LL_TIM_CHANNEL_CH1, LL_TIM_ICPSC_DIV1);
  LL_TIM_IC_SetFilter(TIM2, LL_TIM_CHANNEL_CH1, LL_TIM_IC_FILTER_FDIV1);
  LL_TIM_IC_SetPolarity(TIM2, LL_TIM_CHANNEL_CH1, LL_TIM_IC_POLARITY_FALLING);
  LL_TIM_IC_SetActiveInput(TIM2, LL_TIM_CHANNEL_CH2, LL_TIM_ACTIVEINPUT_DIRECTTI);
  LL_TIM_IC_SetPrescaler(TIM2, LL_TIM_CHANNEL_CH2, LL_TIM_ICPSC_DIV1);
  LL_TIM_SetTriggerOutput(TIM2, LL_TIM_TRGO_RESET);
  LL_TIM_DisableMasterSlaveMode(TIM2);
  /* USER CODE BEGIN TIM2_Init 2 */

    LL_DMA_ClearFlag_FE5(DMA1);
    LL_DMA_ClearFlag_FE6(DMA1);
    LL_DMA_ClearFlag_HT5(DMA1);
    LL_DMA_ClearFlag_HT6(DMA1);
    LL_DMA_ClearFlag_TC5(DMA1);
    LL_DMA_ClearFlag_TC6(DMA1);

  /* USER CODE END TIM2_Init 2 */

}

static void MX_TIM5_Init(void)
{

  LL_TIM_InitTypeDef TIM_InitStruct = {0};

  LL_GPIO_InitTypeDef GPIO_InitStruct = {0};

  /* Peripheral clock enable */
  LL_APB1_GRP1_EnableClock(LL_APB1_GRP1_PERIPH_TIM5);

  LL_AHB1_GRP1_EnableClock(LL_AHB1_GRP1_PERIPH_GPIOA);
  /**TIM5 GPIO Configuration
  PA0-WKUP   ------> TIM5_CH1
  */
  GPIO_InitStruct.Pin = DOUT_Q4_Pin;
  GPIO_InitStruct.Mode = LL_GPIO_MODE_ALTERNATE;
  GPIO_InitStruct.Speed = LL_GPIO_SPEED_FREQ_LOW;
  GPIO_InitStruct.OutputType = LL_GPIO_OUTPUT_PUSHPULL;
  GPIO_InitStruct.Pull = LL_GPIO_PULL_NO;
  GPIO_InitStruct.Alternate = LL_GPIO_AF_2;
  LL_GPIO_Init(DOUT_Q4_GPIO_Port, &GPIO_InitStruct);

  /* TIM5 DMA Init */

  /* TIM5_CH1 Init */
  LL_DMA_SetChannelSelection(DMA1, LL_DMA_STREAM_2, LL_DMA_CHANNEL_6);

  LL_DMA_SetDataTransferDirection(DMA1, LL_DMA_STREAM_2, LL_DMA_DIRECTION_PERIPH_TO_MEMORY);

  LL_DMA_SetStreamPriorityLevel(DMA1, LL_DMA_STREAM_2, LL_DMA_PRIORITY_LOW);

  LL_DMA_SetMode(DMA1, LL_DMA_STREAM_2, LL_DMA_MODE_NORMAL);

  LL_DMA_SetPeriphIncMode(DMA1, LL_DMA_STREAM_2, LL_DMA_PERIPH_NOINCREMENT);

  LL_DMA_SetMemoryIncMode(DMA1, LL_DMA_STREAM_2, LL_DMA_MEMORY_INCREMENT);

  LL_DMA_SetPeriphSize(DMA1, LL_DMA_STREAM_2, LL_DMA_PDATAALIGN_WORD);

  LL_DMA_SetMemorySize(DMA1, LL_DMA_STREAM_2, LL_DMA_MDATAALIGN_WORD);

  LL_DMA_DisableFifoMode(DMA1, LL_DMA_STREAM_2);

  TIM_InitStruct.Prescaler = 0;
  TIM_InitStruct.CounterMode = LL_TIM_COUNTERMODE_UP;
  TIM_InitStruct.Autoreload = 4294967295;
  TIM_InitStruct.ClockDivision = LL_TIM_CLOCKDIVISION_DIV1;
  LL_TIM_Init(TIM5, &TIM_InitStruct);
  LL_TIM_EnableARRPreload(TIM5);
  LL_TIM_SetClockSource(TIM5, LL_TIM_CLOCKSOURCE_INTERNAL);
  LL_TIM_SetTriggerOutput(TIM5, LL_TIM_TRGO_RESET);
  LL_TIM_DisableMasterSlaveMode(TIM5);
  LL_TIM_IC_SetActiveInput(TIM5, LL_TIM_CHANNEL_CH1, LL_TIM_ACTIVEINPUT_DIRECTTI);
  LL_TIM_IC_SetPrescaler(TIM5, LL_TIM_CHANNEL_CH1, LL_TIM_ICPSC_DIV1);
  LL_TIM_IC_SetFilter(TIM5, LL_TIM_CHANNEL_CH1, LL_TIM_IC_FILTER_FDIV1);
  LL_TIM_IC_SetPolarity(TIM5, LL_TIM_CHANNEL_CH1, LL_TIM_IC_POLARITY_RISING);
  /* USER CODE BEGIN TIM5_Init 2 */

    LL_TIM_EnableDMAReq_CC1(TIM5);
    LL_TIM_CC_EnableChannel(TIM5, LL_TIM_CHANNEL_CH1);

    LL_DMA_EnableIT_TC(DMA1, LL_DMA_STREAM_2);
    LL_DMA_EnableIT_TE(DMA1, LL_DMA_STREAM_2);

  /* USER CODE END TIM5_Init 2 */

}

static void MX_TIM8_Init(void)
{

  LL_TIM_InitTypeDef TIM_InitStruct = {0};
  LL_TIM_OC_InitTypeDef TIM_OC_InitStruct = {0};
  LL_TIM_BDTR_InitTypeDef TIM_BDTRInitStruct = {0};

  LL_GPIO_InitTypeDef GPIO_InitStruct = {0};

  /* Peripheral clock enable */
  LL_APB2_GRP1_EnableClock(LL_APB2_GRP1_PERIPH_TIM8);

  /* TIM8 interrupt Init */
  NVIC_SetPriority(TIM8_UP_TIM13_IRQn, NVIC_EncodePriority(NVIC_GetPriorityGrouping(),1, 0));
  NVIC_EnableIRQ(TIM8_UP_TIM13_IRQn);

  TIM_InitStruct.Prescaler = 29;
  TIM_InitStruct.CounterMode = LL_TIM_COUNTERMODE_UP;
  TIM_InitStruct.Autoreload = 39999;
  TIM_InitStruct.ClockDivision = LL_TIM_CLOCKDIVISION_DIV1;
  TIM_InitStruct.RepetitionCounter = 0;
  LL_TIM_Init(TIM8, &TIM_InitStruct);
  LL_TIM_DisableARRPreload(TIM8);
  LL_TIM_SetClockSource(TIM8, LL_TIM_CLOCKSOURCE_INTERNAL);
  LL_TIM_OC_EnablePreload(TIM8, LL_TIM_CHANNEL_CH2);
  TIM_OC_InitStruct.OCMode = LL_TIM_OCMODE_PWM1;
  TIM_OC_InitStruct.OCState = LL_TIM_OCSTATE_DISABLE;
  TIM_OC_InitStruct.OCNState = LL_TIM_OCSTATE_DISABLE;
  TIM_OC_InitStruct.CompareValue = 40;
  TIM_OC_InitStruct.OCPolarity = LL_TIM_OCPOLARITY_HIGH;
  TIM_OC_InitStruct.OCNPolarity = LL_TIM_OCPOLARITY_HIGH;
  TIM_OC_InitStruct.OCIdleState = LL_TIM_OCIDLESTATE_LOW;
  TIM_OC_InitStruct.OCNIdleState = LL_TIM_OCIDLESTATE_LOW;
  LL_TIM_OC_Init(TIM8, LL_TIM_CHANNEL_CH2, &TIM_OC_InitStruct);
  LL_TIM_OC_DisableFast(TIM8, LL_TIM_CHANNEL_CH2);
  LL_TIM_SetTriggerOutput(TIM8, LL_TIM_TRGO_RESET);
  LL_TIM_DisableMasterSlaveMode(TIM8);
  TIM_BDTRInitStruct.OSSRState = LL_TIM_OSSR_DISABLE;
  TIM_BDTRInitStruct.OSSIState = LL_TIM_OSSI_DISABLE;
  TIM_BDTRInitStruct.LockLevel = LL_TIM_LOCKLEVEL_OFF;
  TIM_BDTRInitStruct.DeadTime = 0;
  TIM_BDTRInitStruct.BreakState = LL_TIM_BREAK_DISABLE;
  TIM_BDTRInitStruct.BreakPolarity = LL_TIM_BREAK_POLARITY_HIGH;
  TIM_BDTRInitStruct.AutomaticOutput = LL_TIM_AUTOMATICOUTPUT_ENABLE;
  LL_TIM_BDTR_Init(TIM8, &TIM_BDTRInitStruct);
  LL_AHB1_GRP1_EnableClock(LL_AHB1_GRP1_PERIPH_GPIOC);
  /**TIM8 GPIO Configuration
  PC7   ------> TIM8_CH2
  */
  GPIO_InitStruct.Pin = VSYNC_Pin;
  GPIO_InitStruct.Mode = LL_GPIO_MODE_ALTERNATE;
  GPIO_InitStruct.Speed = LL_GPIO_SPEED_FREQ_LOW;
  GPIO_InitStruct.OutputType = LL_GPIO_OUTPUT_PUSHPULL;
  GPIO_InitStruct.Pull = LL_GPIO_PULL_NO;
  GPIO_InitStruct.Alternate = LL_GPIO_AF_3;
  LL_GPIO_Init(VSYNC_GPIO_Port, &GPIO_InitStruct);

}

static void MX_TIM12_Init(void)
{

  LL_TIM_InitTypeDef TIM_InitStruct = {0};

  /* Peripheral clock enable */
  LL_APB1_GRP1_EnableClock(LL_APB1_GRP1_PERIPH_TIM12);

  TIM_InitStruct.Prescaler = 71;
  TIM_InitStruct.CounterMode = LL_TIM_COUNTERMODE_UP;
  TIM_InitStruct.Autoreload = 65535;
  TIM_InitStruct.ClockDivision = LL_TIM_CLOCKDIVISION_DIV1;
  LL_TIM_Init(TIM12, &TIM_InitStruct);
  LL_TIM_EnableARRPreload(TIM12);
  LL_TIM_SetClockSource(TIM12, LL_TIM_CLOCKSOURCE_INTERNAL);

}

static void MX_USART2_UART_Init(void)
{

  LL_USART_InitTypeDef USART_InitStruct = {0};

  LL_GPIO_InitTypeDef GPIO_InitStruct = {0};

  /* Peripheral clock enable */
  LL_APB1_GRP1_EnableClock(LL_APB1_GRP1_PERIPH_USART2);

  LL_AHB1_GRP1_EnableClock(LL_AHB1_GRP1_PERIPH_GPIOA);
  /**USART2 GPIO Configuration
  PA2   ------> USART2_TX
  PA3   ------> USART2_RX
  */
  GPIO_InitStruct.Pin = USART_TX_Pin|USART_RX_Pin;
  GPIO_InitStruct.Mode = LL_GPIO_MODE_ALTERNATE;
  GPIO_InitStruct.Speed = LL_GPIO_SPEED_FREQ_VERY_HIGH;
  GPIO_InitStruct.OutputType = LL_GPIO_OUTPUT_PUSHPULL;
  GPIO_InitStruct.Pull = LL_GPIO_PULL_NO;
  GPIO_InitStruct.Alternate = LL_GPIO_AF_7;
  LL_GPIO_Init(GPIOA, &GPIO_InitStruct);

  /* USART2 interrupt Init */
  NVIC_SetPriority(USART2_IRQn, NVIC_EncodePriority(NVIC_GetPriorityGrouping(),5, 0));
  NVIC_EnableIRQ(USART2_IRQn);

  USART_InitStruct.BaudRate = 115200;
  USART_InitStruct.DataWidth = LL_USART_DATAWIDTH_8B;
  USART_InitStruct.StopBits = LL_USART_STOPBITS_1;
  USART_InitStruct.Parity = LL_USART_PARITY_NONE;
  USART_InitStruct.TransferDirection = LL_USART_DIRECTION_TX_RX;
  USART_InitStruct.HardwareFlowControl = LL_USART_HWCONTROL_NONE;
  USART_InitStruct.OverSampling = LL_USART_OVERSAMPLING_16;
  LL_USART_Init(USART2, &USART_InitStruct);
  LL_USART_ConfigAsyncMode(USART2);
  LL_USART_Enable(USART2);
  /* USER CODE BEGIN USART2_Init 2 */

    /* USART RX */
    LL_USART_EnableIT_RXNE(USART2);
    LL_USART_EnableIT_ERROR(USART2);

  /* USER CODE END USART2_Init 2 */

}

static void MX_DMA_Init(void)
{

  /* Init with LL driver */
  /* DMA controller clock enable */
  LL_AHB1_GRP1_EnableClock(LL_AHB1_GRP1_PERIPH_DMA2);
  LL_AHB1_GRP1_EnableClock(LL_AHB1_GRP1_PERIPH_DMA1);

  /* DMA interrupt init */
  /* DMA1_Stream2_IRQn interrupt configuration */
  NVIC_SetPriority(DMA1_Stream2_IRQn, NVIC_EncodePriority(NVIC_GetPriorityGrouping(),0, 0));
  NVIC_EnableIRQ(DMA1_Stream2_IRQn);
  /* DMA1_Stream6_IRQn interrupt configuration */
  NVIC_SetPriority(DMA1_Stream6_IRQn, NVIC_EncodePriority(NVIC_GetPriorityGrouping(),0, 0));
  NVIC_EnableIRQ(DMA1_Stream6_IRQn);
  /* DMA2_Stream1_IRQn interrupt configuration */
  NVIC_SetPriority(DMA2_Stream1_IRQn, NVIC_EncodePriority(NVIC_GetPriorityGrouping(),0, 0));
  NVIC_EnableIRQ(DMA2_Stream1_IRQn);

}

static void MX_GPIO_Init(void)
{
  LL_EXTI_InitTypeDef EXTI_InitStruct = {0};
  LL_GPIO_InitTypeDef GPIO_InitStruct = {0};

  /* GPIO Ports Clock Enable */
  LL_AHB1_GRP1_EnableClock(LL_AHB1_GRP1_PERIPH_GPIOC);
  LL_AHB1_GRP1_EnableClock(LL_AHB1_GRP1_PERIPH_GPIOH);
  LL_AHB1_GRP1_EnableClock(LL_AHB1_GRP1_PERIPH_GPIOA);
  LL_AHB1_GRP1_EnableClock(LL_AHB1_GRP1_PERIPH_GPIOB);
  LL_AHB1_GRP1_EnableClock(LL_AHB1_GRP1_PERIPH_GPIOD);

  /**/
  LL_GPIO_SetOutputPin(GPIOC, LTC_HIGH_CURRENT_Pin|ENABLE_SELECT1_Pin);

  /**/
  LL_GPIO_SetOutputPin(GPIOA, LTC_LOW_CURRENT_Pin|LTC_MID_CURRENT_Pin|ADC_CS_Pin|ENABLE_SELECT2_Pin);

  /**/
  LL_GPIO_SetOutputPin(GPIOB, ENABLE_SELECT4_Pin|ENABLE_SELECT3_Pin|CNT_MR_Pin|VLED_CTR_9V_Pin
                          |XDIC_VCC_EN_Pin|ADC_RESET_Pin);

  /**/
  LL_GPIO_ResetOutputPin(GPIOC, PWM_SWITCH_Pin|XDIC_FB_IN_Pin);

  /**/
  LL_GPIO_ResetOutputPin(GPIOB, XC24_5V5_Pin|XDIC_5_7V_Pin|XC24_VCC_EN_Pin|XC24_NSCS_Pin);

  /**/
  LL_GPIO_ResetOutputPin(DEBUG_GPIO_Port, DEBUG_Pin);

  /**/
  GPIO_InitStruct.Pin = B1_Pin;
  GPIO_InitStruct.Mode = LL_GPIO_MODE_INPUT;
  GPIO_InitStruct.Pull = LL_GPIO_PULL_UP;
  LL_GPIO_Init(B1_GPIO_Port, &GPIO_InitStruct);

  /**/
  GPIO_InitStruct.Pin = LTC_HIGH_CURRENT_Pin|PWM_SWITCH_Pin|ENABLE_SELECT1_Pin;
  GPIO_InitStruct.Mode = LL_GPIO_MODE_OUTPUT;
  GPIO_InitStruct.Speed = LL_GPIO_SPEED_FREQ_VERY_HIGH;
  GPIO_InitStruct.OutputType = LL_GPIO_OUTPUT_PUSHPULL;
  GPIO_InitStruct.Pull = LL_GPIO_PULL_NO;
  LL_GPIO_Init(GPIOC, &GPIO_InitStruct);

  /**/
  GPIO_InitStruct.Pin = LTC_LOW_CURRENT_Pin|LTC_MID_CURRENT_Pin|ADC_CS_Pin|ENABLE_SELECT2_Pin;
  GPIO_InitStruct.Mode = LL_GPIO_MODE_OUTPUT;
  GPIO_InitStruct.Speed = LL_GPIO_SPEED_FREQ_VERY_HIGH;
  GPIO_InitStruct.OutputType = LL_GPIO_OUTPUT_PUSHPULL;
  GPIO_InitStruct.Pull = LL_GPIO_PULL_NO;
  LL_GPIO_Init(GPIOA, &GPIO_InitStruct);

  /**/
  GPIO_InitStruct.Pin = XDIC_FB_IN_Pin;
  GPIO_InitStruct.Mode = LL_GPIO_MODE_OUTPUT;
  GPIO_InitStruct.Speed = LL_GPIO_SPEED_FREQ_LOW;
  GPIO_InitStruct.OutputType = LL_GPIO_OUTPUT_PUSHPULL;
  GPIO_InitStruct.Pull = LL_GPIO_PULL_NO;
  LL_GPIO_Init(XDIC_FB_IN_GPIO_Port, &GPIO_InitStruct);

  /**/
  GPIO_InitStruct.Pin = ENABLE_SELECT4_Pin|ENABLE_SELECT3_Pin|XDIC_5_7V_Pin|VLED_CTR_9V_Pin
                          |XDIC_VCC_EN_Pin|XC24_NSCS_Pin;
  GPIO_InitStruct.Mode = LL_GPIO_MODE_OUTPUT;
  GPIO_InitStruct.Speed = LL_GPIO_SPEED_FREQ_VERY_HIGH;
  GPIO_InitStruct.OutputType = LL_GPIO_OUTPUT_PUSHPULL;
  GPIO_InitStruct.Pull = LL_GPIO_PULL_NO;
  LL_GPIO_Init(GPIOB, &GPIO_InitStruct);

  /**/
  GPIO_InitStruct.Pin = XC24_5V5_Pin|CNT_MR_Pin|XC24_VCC_EN_Pin|ADC_RESET_Pin;
  GPIO_InitStruct.Mode = LL_GPIO_MODE_OUTPUT;
  GPIO_InitStruct.Speed = LL_GPIO_SPEED_FREQ_LOW;
  GPIO_InitStruct.OutputType = LL_GPIO_OUTPUT_PUSHPULL;
  GPIO_InitStruct.Pull = LL_GPIO_PULL_NO;
  LL_GPIO_Init(GPIOB, &GPIO_InitStruct);

  /**/
  GPIO_InitStruct.Pin = XDIC_FB_OUT_Pin|XD_SELECT_Pin;
  GPIO_InitStruct.Mode = LL_GPIO_MODE_INPUT;
  GPIO_InitStruct.Pull = LL_GPIO_PULL_NO;
  LL_GPIO_Init(GPIOB, &GPIO_InitStruct);

  /**/
  GPIO_InitStruct.Pin = LL_GPIO_PIN_6|LL_GPIO_PIN_10|LL_GPIO_PIN_11|LL_GPIO_PIN_12;
  GPIO_InitStruct.Mode = LL_GPIO_MODE_ANALOG;
  GPIO_InitStruct.Pull = LL_GPIO_PULL_NO;
  LL_GPIO_Init(GPIOC, &GPIO_InitStruct);

  /**/
  GPIO_InitStruct.Pin = XC_MCLK_Pin;
  GPIO_InitStruct.Mode = LL_GPIO_MODE_ALTERNATE;
  GPIO_InitStruct.Speed = LL_GPIO_SPEED_FREQ_LOW;
  GPIO_InitStruct.OutputType = LL_GPIO_OUTPUT_PUSHPULL;
  GPIO_InitStruct.Pull = LL_GPIO_PULL_NO;
  GPIO_InitStruct.Alternate = LL_GPIO_AF_0;
  LL_GPIO_Init(XC_MCLK_GPIO_Port, &GPIO_InitStruct);

  /**/
  GPIO_InitStruct.Pin = LL_GPIO_PIN_10|LL_GPIO_PIN_11|LL_GPIO_PIN_15;
  GPIO_InitStruct.Mode = LL_GPIO_MODE_ANALOG;
  GPIO_InitStruct.Pull = LL_GPIO_PULL_NO;
  LL_GPIO_Init(GPIOA, &GPIO_InitStruct);

  /**/
  GPIO_InitStruct.Pin = DEBUG_Pin;
  GPIO_InitStruct.Mode = LL_GPIO_MODE_OUTPUT;
  GPIO_InitStruct.Speed = LL_GPIO_SPEED_FREQ_LOW;
  GPIO_InitStruct.OutputType = LL_GPIO_OUTPUT_PUSHPULL;
  GPIO_InitStruct.Pull = LL_GPIO_PULL_NO;
  LL_GPIO_Init(DEBUG_GPIO_Port, &GPIO_InitStruct);

  /**/
  LL_SYSCFG_SetEXTISource(LL_SYSCFG_EXTI_PORTC, LL_SYSCFG_EXTI_LINE4);

  /**/
  EXTI_InitStruct.Line_0_31 = LL_EXTI_LINE_4;
  EXTI_InitStruct.LineCommand = ENABLE;
  EXTI_InitStruct.Mode = LL_EXTI_MODE_IT;
  EXTI_InitStruct.Trigger = LL_EXTI_TRIGGER_FALLING;
  LL_EXTI_Init(&EXTI_InitStruct);

  /**/
  LL_GPIO_SetPinPull(ADC_DRDY_GPIO_Port, ADC_DRDY_Pin, LL_GPIO_PULL_UP);

  /**/
  LL_GPIO_SetPinMode(ADC_DRDY_GPIO_Port, ADC_DRDY_Pin, LL_GPIO_MODE_INPUT);

  /* EXTI interrupt init*/
  NVIC_SetPriority(EXTI4_IRQn, NVIC_EncodePriority(NVIC_GetPriorityGrouping(),0, 0));
  NVIC_EnableIRQ(EXTI4_IRQn);

  /* USER CODE BEGIN MX_GPIO_Init_2 */
    PWM_SWITCH_LO();
    LL_GPIO_SetOutputPin(XC24_VCC_EN_GPIO_Port, XC24_VCC_EN_Pin);

	GPIO_InitStruct.Pin = XDIC_FB_IN_Pin;
    GPIO_InitStruct.Mode = LL_GPIO_MODE_INPUT;
    GPIO_InitStruct.Pull = LL_GPIO_PULL_NO;
    LL_GPIO_Init(XDIC_FB_IN_GPIO_Port, &GPIO_InitStruct);

    GPIO_InitStruct.Pin = XC_MCLK_Pin;
    GPIO_InitStruct.Mode = LL_GPIO_MODE_OUTPUT;
    GPIO_InitStruct.Speed = LL_GPIO_SPEED_FREQ_LOW;
    GPIO_InitStruct.OutputType = LL_GPIO_OUTPUT_PUSHPULL;
    GPIO_InitStruct.Pull = LL_GPIO_PULL_NO;
    LL_GPIO_Init(XC_MCLK_GPIO_Port, &GPIO_InitStruct);
    LL_GPIO_ResetOutputPin(XC_MCLK_GPIO_Port, XC_MCLK_Pin);
  /* USER CODE END MX_GPIO_Init_2 */
}

/* USER CODE BEGIN 4 */
static void JigTestMainTask(void)
{
    if (gb_xd_run_trim_task)
    {
        XD_Trim_Task();
        gb_xd_run_trim_task = false;
    }

    if (gb_xd_run_screen_task)
    {
        XD_Screen_Task();
        gb_xd_run_screen_task = false;
    }

    if (gb_xc_run_trim_task)
    {
        XC_Trim_Task();
        gb_xc_run_trim_task = false;
    }
}

static uint8_t comm_get_rx_packet(rx_packet_t** pData)
{
    uint8_t ret = 0;

    if (gt_rx_uart.RxInCnt != gt_rx_uart.RxOutCnt)
    {
        *pData = gt_rx_uart.Rxbuff + gt_rx_uart.RxOutCnt;

        ++gt_rx_uart.RxOutCnt;
        gt_rx_uart.RxOutCnt &= (uint16_t)(RX_BUFF_SIZE -1);

        ret = 1;
    }

    return ret;
}

static void TaskDebugUart(void)
{
    rx_packet_t* p_data = NULL;

    if (comm_get_rx_packet(&p_data))
    {
        char str_in[RX_PACKET_SIZE + 1] = {0, };
        uint32_t u32_recv_param[6] = {0, };
        double lf_recv_param[6] = {0,};

        memcpy(str_in, p_data->buffer, p_data->length);
        p_data->length = 0;

        if (Command_is_("help") || Command_is_("?"))
        {
            comm_print_help();
        }
/* ----------------- command list - jig ----------------- */
        else if (Command_is_("jig_ic_start"))
        {
            print(LOG_INFO, "\r\n Start timer for freq input capture\r\n");
            JigBD_IF_Start_Input_Capture();
        }
        else if (Command_is_("jig_ic_stop"))
        {
            JigBD_IF_Stop_Input_Capture();
            double input_freq_Hz = JigBD_IF_Get_Input_Capture_Freq();
            print(LOG_INFO, "\r\n Stop timer for freq input capture : %.3f [Hz]\r\n", input_freq_Hz);
        }
        else if (Command_is_("jig_vref_start"))
        {
            print(LOG_INFO, "\r\n ADC RUN\r\n");
            JigBD_IF_Start_MCU_ADC();
        }
        else if (Command_Param_is_("jig_adc", "%d", &u32_recv_param[0]))
        {
            ADS114S08_Select_Input_CH(u32_recv_param[0]);
            LL_mDelay(5);
            ADS114S08_Set_Start(1);
            ADS114S08_Wait_Done();
            uint16_t adc_value = ADS114S08_Get_ADC_Value();
            float adc_voltage = (float)(ADC_VOLT_PER_STEP * adc_value) / CONST_mV_TO_V; // Dac out convert to V
            print(LOG_INFO, "\r\n ADC CH[%d] : %d / %.3f\r\n", u32_recv_param[0], adc_value, adc_voltage);
        }
        else if (Command_Param_is_("jig_ch_sel", "%d", &u32_recv_param[0]))
        {
            print(LOG_INFO, "\r\n Output CH sel - [%u]\r\n", u32_recv_param[0]);
            JigBD_IF_Select_Output_Ch(u32_recv_param[0]);
        }
        else if (Command_Param_is_("jig_xd_vcc", "%u", &u32_recv_param[0]))
        {
            if (u32_recv_param[0])
            {
                print(LOG_INFO, "\r\n XD VCC On [5V]\r\n");
                JigBD_IF_XD_VCC_EN(PWR_ON);
            }
            else
            {
                print(LOG_INFO, "\r\n XD VCC Off [0V]\r\n");
                JigBD_IF_XD_VCC_EN(PWR_OFF);
            }
        }
        else if (Command_Param_is_("jig_xd_vcc_level", "%u", &u32_recv_param[0]))
        {
            if (u32_recv_param[0])
            {
                print(LOG_INFO, "\r\n XD VCC [5.7V]\r\n");
                JigBD_IF_XD_VCC_Level(PWR_ON_5V5);
            }
            else
            {
                print(LOG_INFO, "\r\n XD VCC [5V]\r\n");
                JigBD_IF_XD_VCC_Level(PWR_ON_5V0);
            }
        }
        else if (Command_Param_is_("jig_xc_vcc", "%u", &u32_recv_param[0]))
        {
            if (u32_recv_param[0])
            {
                print(LOG_INFO, "\r\n XC VCC On\r\n");
                JigBD_IF_XC_VCC_EN(PWR_ON);
            }
            else
            {
                print(LOG_INFO, "\r\n XC VCC Off\r\n");
                JigBD_IF_XC_VCC_EN(PWR_OFF);
            }
        }
        else if (Command_Param_is_("jig_xc_vcc_level", "%u", &u32_recv_param[0]))
        {
            if (u32_recv_param[0])
            {
                print(LOG_INFO, "\r\n XC VCC [5.7V]\r\n");
                JigBD_IF_XC_VCC_Level(PWR_ON_5V5);
            }
            else
            {
                print(LOG_INFO, "\r\n XC VCC [5V]\r\n");
                JigBD_IF_XC_VCC_Level(PWR_ON_5V0);
            }
        }
        else if (Command_Param_is_("jig_vled", "%u", &u32_recv_param[0]))
        {
            if (u32_recv_param[0])
            {
                print(LOG_INFO, "\r\n VLED_Enable\r\n");
                JigBD_IF_VLED_9V_EN(PWR_ON);
            }
            else
            {
                print(LOG_INFO, "\r\n VLED_Disable\r\n");
                JigBD_IF_VLED_9V_EN(PWR_OFF);
            }
        }
        else if (Command_Param_is_("jig_ch_sel", "%d", &u32_recv_param[0]))
        {
            if (u32_recv_param[0] > (XD_CH_MAX + 1))
            {
                print(LOG_ERROR, "\r\n Out of CH SEL [%d] [0 - %d]\r\n", u32_recv_param[0], XD_CH_MAX);
            }
            else
            {
                print(LOG_INFO, "\r\n XD CH SEL - [%d]\r\n", u32_recv_param[0]);
                JigBD_IF_Select_Output_Ch(u32_recv_param[0]);
            }
        }
        else if (Command_Param_is_("jig_gain", "%u", &u32_recv_param[0]))
        {
            if (u32_recv_param[0] < GAIN_MAX)
            {
                JigBD_IF_Change_Current_Gain((current_gain_t)u32_recv_param[0]);
            }
            else
            {
                print(LOG_ERROR, "\r\n Out of Jig Current Gain Level [%u] [0 - %u]\r\n", u32_recv_param[0], GAIN_MAX - 1);
            }
        }
        else if (Command_Param_is_("jig_vsync", "%d", &u32_recv_param[0]))
        {
            if (u32_recv_param[0])
            {
                Vsync_Timer_Start();
                print(LOG_INFO, "vsync start\r\n");
            }
            else
            {
                Vsync_Timer_Stop();
                print(LOG_INFO, "vsync stop\r\n");
            }
            print(LOG_INFO, "supply external VLED\r\n");
        }
/* ----------------- command list - xd ----------------- */
        else if (Command_is_("xd_idgen"))
        {
            print(LOG_INFO, "\r\n XD IDGen\r\n");
            JigBD_IF_IdGen_Command();
        }
        else if (Command_is_("xd_reset"))
        {
            print(LOG_INFO, "\r\n XD Reset\r\n");
            JigBD_IF_Reset_Command();
            us_delay(5);
        }
        else if (Command_is_("xd_syncgen"))
        {
            print(LOG_INFO, "\r\n XD Syncgen\r\n");
            JigBD_IF_SyncGen_Command();
            us_delay(5);
        }
        else if (Command_is_("xd_test_en"))
        {
            print(LOG_INFO, "\r\n XD TEST_EN\r\n");
            XDIC_Trim_Init_VREF_CTL();
        }
        else if (Command_is_("xd_icc"))
        {
            JigBD_IF_XD_ICC();
        }
        else if (Command_is_("xd_r_all"))
        {
            print(LOG_INFO, "\r\n Read XD's register all\r\n");
            XDIC_Read_All_Registers();
        }
        else if (Command_Param_is_("xd_w", "%x %x", &u32_recv_param[0], &u32_recv_param[1]))
        {
            if (gb_jig_vsync_active)
            {
                XDIC_Set_Write_Target_Reg(u32_recv_param[0], u32_recv_param[1]);
            }
            else
            {
                XDIC_Write_General_Reg((uint8_t)u32_recv_param[0], (uint16_t)u32_recv_param[1]);
            }
            print(LOG_INFO, "\r\n OK\r\n");
        }
        else if (Command_Param_is_("xd_r", "%x", &u32_recv_param[0]))
        {
            if (gb_jig_vsync_active)
            {
                XDIC_Set_Read_Target_Reg(u32_recv_param[0]);
            }
            else
            {
                uint16_t ret = XDIC_Read_General_Reg((uint8_t)u32_recv_param[0]);
                print(LOG_INFO, "\r\n XDIC Read --> [ 0x%02X - 0x%03X ]\r\n", u32_recv_param[0], ret);
            }
            print(LOG_INFO, "\r\n OK\r\n");
        }
        else if (Command_Param_is_("xd_wt", "%x %x", &u32_recv_param[0], &u32_recv_param[1]))
        {
            XDIC_Write_Mirror_Reg((uint8_t)u32_recv_param[0], (uint16_t)u32_recv_param[1]);
            print(LOG_INFO, "\r\n XD Write : 0x%02X - 0x%02X\r\n", (uint8_t)u32_recv_param[0], (uint16_t)u32_recv_param[1]);
        }
        else if (Command_Param_is_("xd_rt", "%x", &u32_recv_param[0]))
        {
            uint16_t ret = XDIC_Read_Mirror_Reg((uint8_t)u32_recv_param[0]);
            print(LOG_INFO, "\r\n XD Read : 0x%02X : 0x%04X\r\n", u32_recv_param[0], ret);
        }
        else if (Command_Param_is_("xd_ldim", "%d", &u32_recv_param[0]))
        {
            if (u32_recv_param[0] <= 65535)
            {
                print(LOG_INFO, "\r\n Set ldim to [%u]\r\n", u32_recv_param[0]);
                XDIC_Set_LD_Data(u32_recv_param[0]);
            }
            else
            {
                print(LOG_ERROR, "\r\n Out of xdic_ldim [%u] [0 - %u]\r\n", u32_recv_param[0], 65535);
            }
        }
        else if (Command_is_("xd_ldim"))
        {
            print(LOG_INFO, "\r\n ldim - [%u]\r\n", XDIC_Get_LD_Data());
        }
        else if (Command_Param_is_("xd_fbi", "%x", &u32_recv_param[0]))
        {
            if (u32_recv_param[0])
            {
                XD_FBI_HI();
            }
            else
            {
                XD_FBI_LO();
            }
            print(LOG_INFO, "\r\n XD FBI %s\r\n", (u32_recv_param[0] ? "HI" : "LO"));
        }
        else if (Command_is_("xd_fbo"))
        {
            print(LOG_INFO, "\r\n XD FBO %s\r\n", (XD_FBO_READ() ? "HI" : "LO"));
        }
        else if (Command_is_("xd_debug"))
        {
            if (IS_XC24_Support())
            {
                XC24_Init();
            }
            XDIC_Init();
        }
        else if (Command_is_("xd_trim_debug"))
        {
            if (IS_XC24_Support())
            {
                XC24_Init();
            }
            XDIC_Trim_Init();
        }
        else if (Command_is_("xd_trim_vref"))
        {
            XDIC_Trim_Init_VREF_CTL();
            JigBD_IF_Start_MCU_ADC();
            uint16_t vref_adc =  JigBD_IF_Get_MCU_ADC();
            print(LOG_INFO, "\r\n VREF  : %.3f\r\n", JigBD_IF_Convert_MCU_ADC_To_Volt(vref_adc));
        }
        else if (Command_is_("xd_trim_ldo"))
        {
            XDIC_Trim_Init_LDO_CTL();
            JigBD_IF_Start_MCU_ADC();
            uint16_t ldo_adc =  JigBD_IF_Get_MCU_ADC();
            print(LOG_INFO, "\r\n LDO  : %.3f\r\n", JigBD_IF_Convert_MCU_ADC_To_Volt(ldo_adc));
        }
        else if (Command_is_("xd_trim_osc"))
        {
            XDIC_Trim_Init_OSC();
            JigBD_IF_Start_Input_Capture();
            JigBD_IF_Wait_Input_Capture_Done();
            JigBD_IF_Stop_Input_Capture();
            uint16_t osc_cnt = (uint16_t)(JigBD_IF_Get_Input_Capture_Freq());
            float osc_freq = JigBD_IF_Get_Input_Capture_Freq() * XDIC_CONST_FREQ_DIVIDE / CONST_MHz_TO_Hz;
            print(LOG_INFO, "\r\n OSC Freq : %.3f [MHz]\r\n", osc_freq);
        }
        else if (Command_is_("xd_trim_ictl_l"))
        {
            JigBD_IF_VLED_9V_EN(PWR_ON);
            uint16_t iout_adc[XD_CH_SIZE][2] = {0, };
			current_gain_t current_gain = GAIN_MID;
            XDIC_Trim_Init_ICTL_L_CH();
            JigBD_IF_Change_Current_Gain(current_gain);
            for (uint8_t i = 0 ; i < XD_CH_SIZE ; ++i)
            {
                JigBD_IF_Select_Output_Ch(i);
                XDIC_Set_Max_Curr_Vref(600);
                ADS114S08_Set_Start(1);
                ADS114S08_Wait_Done();
                iout_adc[i][0] = ADS114S08_Get_ADC_Value();

                XDIC_Set_Max_Curr_Vref(1000);
                ADS114S08_Set_Start(1);
                ADS114S08_Wait_Done();
                iout_adc[i][1] = ADS114S08_Get_ADC_Value();
                uint16_t adc_average = (iout_adc[i][0] + iout_adc[i][1]) / 2;
                float iout_avg = JigBD_IF_Convert_Adc_To_Current(adc_average, current_gain);
                print(LOG_INFO, "\r\n ICTL_L CH[%d] : %.3f\r\n", i, iout_avg);
            }
        }
        else if (Command_is_("xd_sweep_vref"))
        {
            XDIC_Sweep_LDO();
        }
        else if (Command_is_("5"))
        {
            if (IS_XC24_Support())
            {
                XC24_Init();
            }

            XDIC_Trim_Init();

            JigBD_IF_VLED_9V_EN(PWR_ON);
            print(LOG_DEBUG, "\r\n xd_vled_on\r\n");

            XDIC_Trim_Init_VREF_CTL();
            JigBD_IF_Start_MCU_ADC();
            uint16_t vref_adc =  JigBD_IF_Get_MCU_ADC();
            print(LOG_INFO, "\r\n VREF  : %.3f\r\n", JigBD_IF_Convert_MCU_ADC_To_Volt(vref_adc));

            XDIC_Trim_Init_LDO_CTL();
            JigBD_IF_Start_MCU_ADC();
            uint16_t ldo_adc =  JigBD_IF_Get_MCU_ADC();
            print(LOG_INFO, "\r\n LDO  : %.3f\r\n", JigBD_IF_Convert_MCU_ADC_To_Volt(ldo_adc));

            XDIC_Trim_Init_OSC();
            JigBD_IF_Start_Input_Capture();
            JigBD_IF_Wait_Input_Capture_Done();
            JigBD_IF_Stop_Input_Capture();

            uint16_t osc_cnt = (uint16_t)(JigBD_IF_Get_Input_Capture_Freq());
            float osc_freq = JigBD_IF_Get_Input_Capture_Freq() * XDIC_CONST_FREQ_DIVIDE / CONST_MHz_TO_Hz;
            print(LOG_INFO, "\r\n OSC Freq : %.3f [MHz]\r\n", osc_freq);

            uint16_t iout_adc[XD_CH_SIZE][2] = {0, };
            XDIC_Trim_Init_ICTL_L_CH();
            JigBD_IF_Change_Current_Gain(GAIN_MID);
            float iout_avg[4] = {0, };
            for (uint8_t i = 0 ; i < XD_CH_SIZE ; ++i)
            {
                JigBD_IF_Select_Output_Ch(i);
                XDIC_Set_Max_Curr_Vref(600);
                ADS114S08_Set_Start(1);
                ADS114S08_Wait_Done();
                iout_adc[i][0] = ADS114S08_Get_ADC_Value();
                XDIC_Set_Max_Curr_Vref(1000);
                ADS114S08_Set_Start(1);
                ADS114S08_Wait_Done();
                iout_adc[i][1] = ADS114S08_Get_ADC_Value();
                uint16_t adc_average = (iout_adc[i][0] + iout_adc[i][1]) / 2;
                iout_avg[i] = JigBD_IF_Convert_Adc_To_Current(adc_average, GAIN_MID);
            }

            print(LOG_INFO, "%.3f, %.3f, %.3f, %.3f, %.3f, %.3f, %.3f,", JigBD_IF_Convert_MCU_ADC_To_Volt(vref_adc), JigBD_IF_Convert_MCU_ADC_To_Volt(ldo_adc), osc_freq, iout_avg[0], iout_avg[1], iout_avg[2], iout_avg[3]);
            XDIC_Dump_Trim_Regs_OneLine();
        }
        else if (Command_is_("xd_trim_ictl_h"))
        {
            JigBD_IF_VLED_9V_EN(PWR_ON);
            uint16_t iout_adc[XD_CH_SIZE][2] = {0, };
            XDIC_Trim_Init_ICTL_H_CH();
			current_gain_t current_gain = GAIN_HIGH;
            JigBD_IF_Change_Current_Gain(current_gain);
            for (uint8_t i = 0 ; i < XD_CH_SIZE ; ++i)
            {
                JigBD_IF_Select_Output_Ch(i);
                XDIC_Set_Max_Curr_Vref(600);
                ADS114S08_Set_Start(1);
                ADS114S08_Wait_Done();
                iout_adc[i][0] = ADS114S08_Get_ADC_Value();
                XDIC_Set_Max_Curr_Vref(1000);
                ADS114S08_Set_Start(1);
                ADS114S08_Wait_Done();
                iout_adc[i][1] = ADS114S08_Get_ADC_Value();
                uint16_t adc_average = (iout_adc[i][0] + iout_adc[i][1]) / 2;
                float iout_avg = JigBD_IF_Convert_Adc_To_Current(adc_average, current_gain);
                print(LOG_INFO, "\r\n ICTL_H CH[%d] : %.3f\r\n", i, iout_avg);
            }
        }
        else if (Command_Param_is_("xd_ch", "%d %d", &u32_recv_param[0], &u32_recv_param[1]))
        {
            if (u32_recv_param[0] < (XD_CH_MAX + 1))
            {
                if (u32_recv_param[0])
                {
                    uint16_t ch_en_val = XDIC_Get_General_Reg(XDIC_ADDR_CHANNEL_ENABLE);
                    ch_en_val &= ~(1 << (u32_recv_param[0] - 1));
                    if (u32_recv_param[1] == 1)
                    {
                        ch_en_val |= (1 << (u32_recv_param[0] - 1));
                    }
                    XDIC_Write_General_Reg(XDIC_ADDR_CHANNEL_ENABLE, ch_en_val);
                }
                else
                {
                    uint16_t ch_en_val = 0xFFF;
                    XDIC_Write_General_Reg(XDIC_ADDR_CHANNEL_ENABLE, ch_en_val);
                }
            }
            else
            {
                print(LOG_ERROR, "\r\n Out of CH [%u] [0 - %u]\r\n", u32_recv_param[0], XD_CH_MAX - 1);
            }
        }
        else if (Command_Param_is_("xd_line_delay", "%d", &u32_recv_param[0]))
        {
            if (u32_recv_param[0])
            {
                uint16_t delay_per_ch = 16383U / 4;
                uint16_t delay_msb_accumulator[2] = {0, };
                uint16_t delay_ch[4] = {0, };

                for (uint8_t ch = 0 ; ch < XD_CH_SIZE ; ++ch)
                {
                    delay_ch[ch] = delay_per_ch * ch;
                    uint16_t delay_lsb = ((delay_ch[ch] & 0x0FFF) >>  0);
                    uint16_t delay_msb = ((delay_ch[ch] & 0x3000) >> 12);

                    delay_msb_accumulator[ch / 6] |= (delay_msb << (2 * (ch % 6)));

                    print(LOG_DEBUG, "[%s] delay_ch[%u] = %u / msb = %u / lsb = %u\r\n", __func__, ch, delay_ch[ch], delay_msb, delay_lsb);

                    XDIC_Write_General_Reg(XDIC_ADDR_DELAY_CH_01 + ch, delay_lsb);
                }
                XDIC_Write_General_Reg(XDIC_ADDR_DELAY_CH_EXTEND, delay_msb_accumulator[0]);
            }
            else
            {
                for (uint8_t ch = 0 ; ch < XD_CH_SIZE ; ++ch)
                {
                    XDIC_Write_General_Reg(XDIC_ADDR_DELAY_CH_01 + ch, 0);
                }
                XDIC_Write_General_Reg(XDIC_ADDR_DELAY_CH_EXTEND, 0);
            }
        }
/* ----------------- command list - xc ----------------- */
        else if (Command_is_("xc_debug"))
        {
            XC24_Init();
        }
        else if (Command_is_("xc_trim_debug"))
        {
            XC24_Trim_Init();
        }
        else if (Command_Param_is_("xc_w", "%x %x", &u32_recv_param[0], &u32_recv_param[1]))
        {
            print(LOG_INFO, "\r\n XC Write : 0x%02X - 0x%02X\r\n", u32_recv_param[0], u32_recv_param[1]);
            XC24_Write_Register((uint16_t)u32_recv_param[0], (uint16_t)u32_recv_param[1]);
        }
        else if (Command_is_("xc_r_all"))
        {
            XC24_Read_Register_All();
        }
        else if (Command_Param_is_("xc_r", "%x", &u32_recv_param[0]))
        {
            uint16_t ret = XC24_Read_Register((uint8_t)u32_recv_param[0]);
            print(LOG_INFO, "\r\n XC Read : 0x%02X : 0x%04X\r\n", u32_recv_param[0], ret);
        }
        else if (Command_is_("xc_trim_ldo"))
        {
            ADS114S08_Select_Input_CH(ADS114S08_CH_XC_LDO);
            LL_mDelay(1);
            ADS114S08_Set_Start(1);
            ADS114S08_Wait_Done();

            uint16_t ext_adc_value = ADS114S08_Get_ADC_Value();
            float vctl_ldo_level = (float)(ADC_VOLT_PER_STEP * ext_adc_value) / CONST_mV_TO_V; // Dac out convert to V
            print(LOG_INFO, "Screen  LDO_ADC [%u] -> LDO_LEVEL : %.3f\r\n", ext_adc_value, vctl_ldo_level);
        }
        else if (Command_is_("xc_trim_osc"))
        {
            XC24_Trim_Init_OSC();
            LL_mDelay(1);
            JigBD_IF_Start_Input_Capture();
            JigBD_IF_Wait_Input_Capture_Done();
            JigBD_IF_Stop_Input_Capture();
            float osc_freq = JigBD_IF_Get_Input_Capture_Freq() * XC24_CONST_FREQ_DIVIDE / CONST_MHz_TO_Hz;
            print(LOG_INFO, "Screen  OSC : %.3f\r\n", osc_freq);
        }
        else if (Command_is_("xc_trim_dac"))
        {
            XC24_Trim_Init_DAC_Gain();
            ADS114S08_Select_Input_CH(ADS114S08_CH_XC_DAC);
            uint16_t dac_input[4] = {248, 1241, 2482, 3723};
            for (uint8_t i = 0 ; i < 4 ; ++i)
            {
                XC24_Write_Register(XC24_ADDR_CURRENT_TARGET_DAC, dac_input[i]);
                LL_mDelay(1);
                ADS114S08_Set_Start(1);
                ADS114S08_Wait_Done();

                uint16_t ext_adc_value = ADS114S08_Get_ADC_Value();
                float dac_val = (float)(ADC_VOLT_PER_STEP * ext_adc_value) / CONST_mV_TO_V;
                print(LOG_INFO, "%u, %.4f\r\n", dac_input[i], dac_val);
            }
        }
        else if (Command_Param_is_("xc_use", "%d", &u32_recv_param[0]))
        {
            if (u32_recv_param[0] < 2)
            {
                if (u32_recv_param[0])
                {
                    USE_XC24(true);
                    print(LOG_INFO, "\r\n SUPPORT_XC24\r\n");
                }
                else
                {
                    USE_XC24(false);
                    print(LOG_INFO, "\r\n NOT_SUPPORT_XC24\r\n");
                }
            }
            else
            {
                print(LOG_ERROR, "\r\n Out of xc_use [%u] [0 - %u]\r\n", u32_recv_param[0], 1);
            }
        }
/* ----------------- command list - ui ----------------- */
        else if (Command_is_("xd_trim_start") || Command_is_("1"))
        {
            print(LOG_INFO, "\r\n XD Trim Start \r\n");
            XD_Trim_IF_Trim_Start();
        }
        else if (Command_is_("xd_screen_start") || Command_is_("2"))
        {
            print(LOG_INFO, "\r\n XDIC Screen Start \r\n");
            XD_Trim_IF_Screen_Start();
        }
        else if (Command_is_("xd_dimming_start") || Command_is_("3"))
        {
            if (IS_XC24_Support())
            {
                XC24_Init();
            }

            XDIC_Init();

            JigBD_IF_VLED_9V_EN(PWR_ON);
            print(LOG_DEBUG, "\r\n xd_vled_on\r\n");

            Vsync_Timer_Start();
            print(LOG_INFO, "vsync start\r\n");

            XDIC_Set_LD_Data(100);
        }
        else if (Command_is_("xc_trim_start") || Command_is_("4"))
        {
            print(LOG_INFO, "\r\n XC Trim Start \r\n");
            XC_Trim_IF_Trim_Start();
        }
        else if (Command_Param_is_("log_lv", "%d", &u32_recv_param[0]))
        {
            if (u32_recv_param[0] < LOG_MAX)
            {
                print(LOG_INFO, "\r\n log_level - [%u]\r\n", u32_recv_param[0]);
                gt_log_lv = (LOG_LV_T)u32_recv_param[0];
            }
            else
            {
                print(LOG_ERROR, "\r\n Out of log_lv [%u] [0 - %u]\r\n", u32_recv_param[0], LOG_MAX - 1);
            }
        }
        else if (Command_is_("reset"))
        {
            print(LOG_INFO, "\r\n system reset \r\n");
            NVIC_SystemReset();
        }
        else
        {
            print(LOG_INFO, "\r\n What?\n\r");
        }
    }
}

__STATIC_INLINE void UART_PutChar(uint8_t data)
{
    /* Echo received character on TX */
    if ((data == '\n') || (data == '\r'))
    {
        LL_USART_TransmitData8(USART2, '\r');
        LL_USART_TransmitData8(USART2, '\n');
    }
    else
    {
        LL_USART_TransmitData8(USART2, data);
    }

    /* Loop until the end of transmission */
    while (RESET == LL_USART_IsActiveFlag_TXE(USART2));
}

void comm_rx_handler(uint8_t rx)
{
    UART_PutChar(rx);

    if ((rx == '\n') || (rx == '\r'))
    {
        if (gt_rx_uart.Rxbuff[gt_rx_uart.RxInCnt].length < (RX_PACKET_SIZE - 1))
        {
            gt_rx_uart.Rxbuff[gt_rx_uart.RxInCnt].buffer[gt_rx_uart.Rxbuff[gt_rx_uart.RxInCnt].length] = 0;
        }
        else
        {
            gt_rx_uart.Rxbuff[gt_rx_uart.RxInCnt].buffer[(RX_PACKET_SIZE - 1)] = 0;
        }

        ++gt_rx_uart.RxInCnt;
        gt_rx_uart.RxInCnt &= (uint16_t)(RX_BUFF_SIZE - 1);
    }
    else if (rx == UART_BACKSPACE)
    {
        if (gt_rx_uart.Rxbuff[gt_rx_uart.RxInCnt].length)
        {
            uint8_t temp[2] = {' ', UART_BACKSPACE};

            UART_PutChar(temp[0]);
            UART_PutChar(temp[1]);
            --gt_rx_uart.Rxbuff[gt_rx_uart.RxInCnt].length;
        }
    }
    else
    {
        if (gt_rx_uart.Rxbuff[gt_rx_uart.RxInCnt].length < (RX_PACKET_SIZE - 1))
        {
            gt_rx_uart.Rxbuff[gt_rx_uart.RxInCnt].buffer[gt_rx_uart.Rxbuff[gt_rx_uart.RxInCnt].length] = rx;
            ++gt_rx_uart.Rxbuff[gt_rx_uart.RxInCnt].length;

            if (gt_rx_uart.Rxbuff[gt_rx_uart.RxInCnt].buffer[0] == 0x1B)
            {
                if (gt_rx_uart.Rxbuff[gt_rx_uart.RxInCnt].buffer[1] == 0x5B)
                {
                    if (gt_rx_uart.Rxbuff[gt_rx_uart.RxInCnt].buffer[2] == 0x41)
                    {
                        print(LOG_INFO, "\r\n\r\n");
                        /* copy */
                        for (uint8_t i = 0 ; i < 64 ; ++i)
                        {
                            if (gt_rx_uart.RxInCnt)
                            {
                                if (gt_rx_uart.Rxbuff[gt_rx_uart.RxInCnt-1].buffer[i])
                                {
                                    gt_rx_uart.Rxbuff[gt_rx_uart.RxInCnt].buffer[i] = gt_rx_uart.Rxbuff[gt_rx_uart.RxInCnt-1].buffer[i];
                                    print(LOG_INFO, "%c", gt_rx_uart.Rxbuff[gt_rx_uart.RxInCnt].buffer[i]);
                                }
                                else
                                {
                                    gt_rx_uart.Rxbuff[gt_rx_uart.RxInCnt].length = i;
                                    break;
                                }
                            }
                            else
                            {
                                if (gt_rx_uart.Rxbuff[RX_BUFF_SIZE-1].buffer[i])
                                {
                                    gt_rx_uart.Rxbuff[gt_rx_uart.RxInCnt].buffer[i] = gt_rx_uart.Rxbuff[RX_BUFF_SIZE-1].buffer[i];
                                    print(LOG_INFO, "%c", gt_rx_uart.Rxbuff[gt_rx_uart.RxInCnt].buffer[i]);
                                }
                                else
                                {
                                    gt_rx_uart.Rxbuff[gt_rx_uart.RxInCnt].length = i;
                                    break;
                                }
                            }
                        }
                    }
                }
            }
        }
        else
        {
            //print(LOG_ERROR, "buffer limit...\r\n");
        }
    }
}
/* USER CODE END 4 */

void Error_Handler(void)
{
  __disable_irq();
  while (1)
  {
  }
}
